AUTOSAR XML (schema 3.1.2)
package /Components/SWC_CoTq
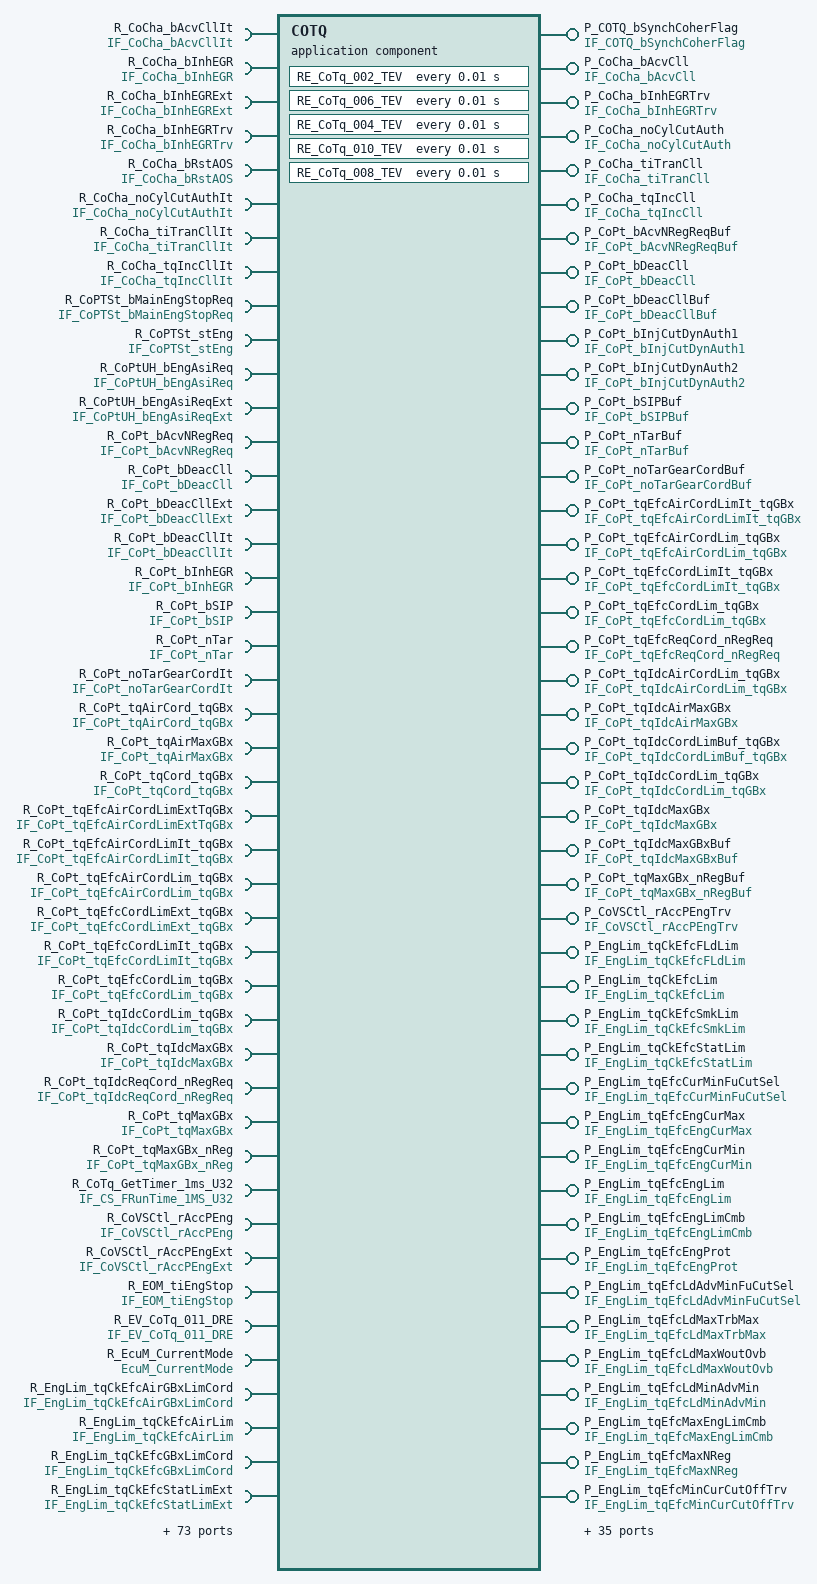
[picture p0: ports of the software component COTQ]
  application software component type COTQ  # CoTq
    79 x provide port:
      P_COTQ_bSynchCoherFlag: unqueued-sender-com-spec{data-element=COTQ_bSynchCoherFlag, can-invalidate=false, init-value=ConstantValue}, provided-interface=IF_COTQ_bSynchCoherFlag  # Requirement: 01552_10_02369-CoTq.I999(0)
      P_CoCha_bAcvCll: unqueued-sender-com-spec{data-element=CoCha_bAcvCll, can-invalidate=false, init-value=ConstantValue1}, provided-interface=IF_CoCha_bAcvCll  # Requirement: 01552_10_02369-CoTq.I010(0)
      P_CoCha_bInhEGRTrv: unqueued-sender-com-spec{data-element=CoCha_bInhEGRTrv, can-invalidate=false, init-value=ConstantValue3}, provided-interface=IF_CoCha_bInhEGRTrv  # Requirement: 01552_10_02369-CoTq.I011(0)
      P_CoCha_noCylCutAuth: unqueued-sender-com-spec{data-element=CoCha_noCylCutAuth, can-invalidate=false, init-value=ConstantValue5}, provided-interface=IF_CoCha_noCylCutAuth  # Requirement: 01552_10_02369-CoTq.I012(0)
      P_CoCha_tiTranCll: unqueued-sender-com-spec{data-element=CoCha_tiTranCll, can-invalidate=false, init-value=ConstantValue7}, provided-interface=IF_CoCha_tiTranCll  # Requirement: 01552_10_02369-CoTq.I013(0)
      P_CoCha_tqIncCll: unqueued-sender-com-spec{data-element=CoCha_tqIncCll, can-invalidate=false, init-value=ConstantValue9}, provided-interface=IF_CoCha_tqIncCll  # Requirement: 01552_10_02369-CoTq.I014(0)
      P_CoPt_bAcvNRegReqBuf: unqueued-sender-com-spec{data-element=CoPt_bAcvNRegReqBuf, can-invalidate=false, init-value=ConstantValue11}, provided-interface=IF_CoPt_bAcvNRegReqBuf  # Requirement: 01552_10_02369-CoTq.I179(0)
      P_CoPt_bDeacCll: unqueued-sender-com-spec{data-element=CoPt_bDeacCll, can-invalidate=false, init-value=ConstantValue13}, provided-interface=IF_CoPt_bDeacCll  # Requirement: 01552_10_02369-CoTq.I015(0)
      P_CoPt_bDeacCllBuf: unqueued-sender-com-spec{data-element=CoPt_bDeacCllBuf, can-invalidate=false, init-value=ConstantValue15}, provided-interface=IF_CoPt_bDeacCllBuf  # Requirement: 01552_10_02369-CoTq.I180(0)
      P_CoPt_bInjCutDynAuth1: unqueued-sender-com-spec{data-element=CoPt_bInjCutDynAuth1, can-invalidate=false, init-value=ConstantValue17}, provided-interface=IF_CoPt_bInjCutDynAuth1  # Requirement: 01552_10_02369-CoTq.I181(0)
      P_CoPt_bInjCutDynAuth2: unqueued-sender-com-spec{data-element=CoPt_bInjCutDynAuth2, can-invalidate=false, init-value=ConstantValue19}, provided-interface=IF_CoPt_bInjCutDynAuth2  # Requirement: 01552_10_02369-CoTq.I182(0)
      P_CoPt_bSIPBuf: unqueued-sender-com-spec{data-element=CoPt_bSIPBuf, can-invalidate=false, init-value=ConstantValue21}, provided-interface=IF_CoPt_bSIPBuf  # Requirement: 01552_10_02369-CoTq.I183(0)
      P_CoPt_nTarBuf: unqueued-sender-com-spec{data-element=CoPt_nTarBuf, can-invalidate=false, init-value=ConstantValue23}, provided-interface=IF_CoPt_nTarBuf  # Requirement: 01552_10_02369-CoTq.I185(0)
      P_CoPt_noTarGearCordBuf: unqueued-sender-com-spec{data-element=CoPt_noTarGearCordBuf, can-invalidate=false, init-value=ConstantValue25}, provided-interface=IF_CoPt_noTarGearCordBuf  # Requirement: 01552_10_02369-CoTq.I184(0)
      P_CoPt_tqEfcAirCordLimIt_tqGBx: unqueued-sender-com-spec{data-element=CoPt_tqEfcAirCordLimIt_tqGBx, can-invalidate=false, init-value=ConstantValue27}, provided-interface=IF_CoPt_tqEfcAirCordLimIt_tqGBx  # Requirement: 01552_10_02369-CoTq.I001(0)
      P_CoPt_tqEfcAirCordLim_tqGBx: unqueued-sender-com-spec{data-element=CoPt_tqEfcAirCordLim_tqGBx, can-invalidate=false, init-value=ConstantValue29}, provided-interface=IF_CoPt_tqEfcAirCordLim_tqGBx  # Requirement: 01552_10_02369-CoTq.I016(0)
      P_CoPt_tqEfcCordLimIt_tqGBx: unqueued-sender-com-spec{data-element=CoPt_tqEfcCordLimIt_tqGBx, can-invalidate=false, init-value=ConstantValue31}, provided-interface=IF_CoPt_tqEfcCordLimIt_tqGBx  # Requirement: 01552_10_02369-CoTq.I002(0)
      P_CoPt_tqEfcCordLim_tqGBx: unqueued-sender-com-spec{data-element=CoPt_tqEfcCordLim_tqGBx, can-invalidate=false, init-value=ConstantValue33}, provided-interface=IF_CoPt_tqEfcCordLim_tqGBx  # Requirement: 01552_10_02369-CoTq.I017(0)
      P_CoPt_tqEfcReqCord_nRegReq: unqueued-sender-com-spec{data-element=CoPt_tqEfcReqCord_nRegReq, can-invalidate=false, init-value=ConstantValue35}, provided-interface=IF_CoPt_tqEfcReqCord_nRegReq  # Requirement: 01552_10_02369-CoTq.I105(0)
      P_CoPt_tqIdcAirCordLim_tqGBx: unqueued-sender-com-spec{data-element=CoPt_tqIdcAirCordLim_tqGBx, can-invalidate=false, init-value=ConstantValue37}, provided-interface=IF_CoPt_tqIdcAirCordLim_tqGBx  # Requirement: 01552_10_02369-CoTq.I084(0)
      P_CoPt_tqIdcAirMaxGBx: unqueued-sender-com-spec{data-element=CoPt_tqIdcAirMaxGBx, can-invalidate=false, init-value=ConstantValue39}, provided-interface=IF_CoPt_tqIdcAirMaxGBx  # Requirement: 01552_10_02369-CoTq.I085(0)
      P_CoPt_tqIdcCordLimBuf_tqGBx: unqueued-sender-com-spec{data-element=CoPt_tqIdcCordLimBuf_tqGBx, can-invalidate=false, init-value=ConstantValue41}, provided-interface=IF_CoPt_tqIdcCordLimBuf_tqGBx  # Requirement: 01552_10_02369-CoTq.I186(0)
      P_CoPt_tqIdcCordLim_tqGBx: unqueued-sender-com-spec{data-element=CoPt_tqIdcCordLim_tqGBx, can-invalidate=false, init-value=ConstantValue43}, provided-interface=IF_CoPt_tqIdcCordLim_tqGBx  # Requirement: 01552_10_02369-CoTq.I086(0)
      P_CoPt_tqIdcMaxGBx: unqueued-sender-com-spec{data-element=CoPt_tqIdcMaxGBx, can-invalidate=false, init-value=ConstantValue45}, provided-interface=IF_CoPt_tqIdcMaxGBx  # Requirement: 01552_10_02369-CoTq.I087(0)
      P_CoPt_tqIdcMaxGBxBuf: unqueued-sender-com-spec{data-element=CoPt_tqIdcMaxGBxBuf, can-invalidate=false, init-value=ConstantValue47}, provided-interface=IF_CoPt_tqIdcMaxGBxBuf  # Requirement: 01552_10_02369-CoTq.I187(0)
      P_CoPt_tqMaxGBx_nRegBuf: unqueued-sender-com-spec{data-element=CoPt_tqMaxGBx_nRegBuf, can-invalidate=false, init-value=ConstantValue49}, provided-interface=IF_CoPt_tqMaxGBx_nRegBuf  # Requirement: 01552_10_02369-CoTq.I188(0)
      P_CoVSCtl_rAccPEngTrv: unqueued-sender-com-spec{data-element=CoVSCtl_rAccPEngTrv, can-invalidate=false, init-value=ConstantValue51}, provided-interface=IF_CoVSCtl_rAccPEngTrv  # Requirement: 01552_10_02369-CoTq.I018(0)
      P_EngLim_tqCkEfcFLdLim: unqueued-sender-com-spec{data-element=EngLim_tqCkEfcFLdLim, can-invalidate=false, init-value=ConstantValue53}, provided-interface=IF_EngLim_tqCkEfcFLdLim  # Requirement: 01552_10_02369-CoTq.I118(0)
      P_EngLim_tqCkEfcLim: unqueued-sender-com-spec{data-element=EngLim_tqCkEfcLim, can-invalidate=false, init-value=ConstantValue55}, provided-interface=IF_EngLim_tqCkEfcLim  # Requirement: 01552_10_02369-CoTq.I119(0)
      P_EngLim_tqCkEfcSmkLim: unqueued-sender-com-spec{data-element=EngLim_tqCkEfcSmkLim, can-invalidate=false, init-value=ConstantValue57}, provided-interface=IF_EngLim_tqCkEfcSmkLim  # Requirement: 01552_10_02369-CoTq.I120(0)
      P_EngLim_tqCkEfcStatLim: unqueued-sender-com-spec{data-element=EngLim_tqCkEfcStatLim, can-invalidate=false, init-value=ConstantValue59}, provided-interface=IF_EngLim_tqCkEfcStatLim  # Requirement: 01552_10_02369-CoTq.I019(0)
      P_EngLim_tqEfcCurMinFuCutSel: unqueued-sender-com-spec{data-element=EngLim_tqEfcCurMinFuCutSel, can-invalidate=false, init-value=ConstantValue61}, provided-interface=IF_EngLim_tqEfcCurMinFuCutSel  # Requirement: 01552_10_02369-CoTq.I106(0)
      P_EngLim_tqEfcEngCurMax: unqueued-sender-com-spec{data-element=EngLim_tqEfcEngCurMax, can-invalidate=false, init-value=ConstantValue63}, provided-interface=IF_EngLim_tqEfcEngCurMax  # Requirement: 01552_10_02369-CoTq.I121(0)
      P_EngLim_tqEfcEngCurMin: unqueued-sender-com-spec{data-element=EngLim_tqEfcEngCurMin, can-invalidate=false, init-value=ConstantValue65}, provided-interface=IF_EngLim_tqEfcEngCurMin  # Requirement: 01552_10_02369-CoTq.I107(0)
      P_EngLim_tqEfcEngLim: unqueued-sender-com-spec{data-element=EngLim_tqEfcEngLim, can-invalidate=false, init-value=ConstantValue67}, provided-interface=IF_EngLim_tqEfcEngLim  # Requirement: 01552_10_02369-CoTq.I108(0)
      P_EngLim_tqEfcEngLimCmb: unqueued-sender-com-spec{data-element=EngLim_tqEfcEngLimCmb, can-invalidate=false, init-value=ConstantValue69}, provided-interface=IF_EngLim_tqEfcEngLimCmb  # Requirement: 01552_10_02369-CoTq.I109(0)
      P_EngLim_tqEfcEngProt: unqueued-sender-com-spec{data-element=EngLim_tqEfcEngProt, can-invalidate=false, init-value=ConstantValue71}, provided-interface=IF_EngLim_tqEfcEngProt  # Requirement: 01552_10_02369-CoTq.I122(0)
      P_EngLim_tqEfcLdAdvMinFuCutSel: unqueued-sender-com-spec{data-element=EngLim_tqEfcLdAdvMinFuCutSel, can-invalidate=false, init-value=ConstantValue73}, provided-interface=IF_EngLim_tqEfcLdAdvMinFuCutSel  # Requirement: 01552_10_02369-CoTq.I110(0)
      P_EngLim_tqEfcLdMaxTrbMax: unqueued-sender-com-spec{data-element=EngLim_tqEfcLdMaxTrbMax, can-invalidate=false, init-value=ConstantValue75}, provided-interface=IF_EngLim_tqEfcLdMaxTrbMax  # Requirement: 01552_10_02369-CoTq.I123(0)
      P_EngLim_tqEfcLdMaxWoutOvb: unqueued-sender-com-spec{data-element=EngLim_tqEfcLdMaxWoutOvb, can-invalidate=false, init-value=ConstantValue77}, provided-interface=IF_EngLim_tqEfcLdMaxWoutOvb  # Requirement: 01552_10_02369-CoTq.I111(0)
      P_EngLim_tqEfcLdMinAdvMin: unqueued-sender-com-spec{data-element=EngLim_tqEfcLdMinAdvMin, can-invalidate=false, init-value=ConstantValue79}, provided-interface=IF_EngLim_tqEfcLdMinAdvMin  # Requirement: 01552_10_02369-CoTq.I112(0)
      P_EngLim_tqEfcMaxEngLimCmb: unqueued-sender-com-spec{data-element=EngLim_tqEfcMaxEngLimCmb, can-invalidate=false, init-value=ConstantValue81}, provided-interface=IF_EngLim_tqEfcMaxEngLimCmb  # Requirement: 01552_10_02369-CoTq.I113(0)
      P_EngLim_tqEfcMaxNReg: unqueued-sender-com-spec{data-element=EngLim_tqEfcMaxNReg, can-invalidate=false, init-value=ConstantValue83}, provided-interface=IF_EngLim_tqEfcMaxNReg  # Requirement: 01552_10_02369-CoTq.I124(0)
      P_EngLim_tqEfcMinCurCutOffTrv: unqueued-sender-com-spec{data-element=EngLim_tqEfcMinCurCutOffTrv, can-invalidate=false, init-value=ConstantValue85}, provided-interface=IF_EngLim_tqEfcMinCurCutOffTrv  # Requirement: 01552_10_02369-CoTq.I125(0)
      P_EngLim_tqEfcMinCurTrv: unqueued-sender-com-spec{data-element=EngLim_tqEfcMinCurTrv, can-invalidate=false, init-value=ConstantValue87}, provided-interface=IF_EngLim_tqEfcMinCurTrv  # Requirement: 01552_10_02369-CoTq.I126(0)
      P_EngLim_tqEfcMinEngLimCmb: unqueued-sender-com-spec{data-element=EngLim_tqEfcMinEngLimCmb, can-invalidate=false, init-value=ConstantValue89}, provided-interface=IF_EngLim_tqEfcMinEngLimCmb  # Requirement: 01552_10_02369-CoTq.I114(0)
      P_EngLim_tqEfcPresUsThrMax: unqueued-sender-com-spec{data-element=EngLim_tqEfcPresUsThrMax, can-invalidate=false, init-value=ConstantValue91}, provided-interface=IF_EngLim_tqEfcPresUsThrMax  # Requirement: 01552_10_02369-CoTq.I127(0)
      P_EngLim_tqEfcRed: unqueued-sender-com-spec{data-element=EngLim_tqEfcRed, can-invalidate=false, init-value=ConstantValue93}, provided-interface=IF_EngLim_tqEfcRed  # Requirement: 01552_10_02369-CoTq.I128(0)
      P_EngLim_tqEfcSfty: unqueued-sender-com-spec{data-element=EngLim_tqEfcSfty, can-invalidate=false, init-value=ConstantValue95}, provided-interface=IF_EngLim_tqEfcSfty  # Requirement: 01552_10_02369-CoTq.I129(0)
      P_EngLim_tqEfcSyst: unqueued-sender-com-spec{data-element=EngLim_tqEfcSyst, can-invalidate=false, init-value=ConstantValue97}, provided-interface=IF_EngLim_tqEfcSyst  # Requirement: 01552_10_02369-CoTq.I130(0)
      P_ThMgt_tqEfcLimAntiBoilProt: unqueued-sender-com-spec{data-element=ThMgt_tqEfcLimAntiBoilProt, can-invalidate=false, init-value=ConstantValue99}, provided-interface=IF_ThMgt_tqEfcLimAntiBoilProt  # Requirement: 01552_10_02369-CoTq.I131(0)
      P_TqDem_facGainFilTrv_nCk: unqueued-sender-com-spec{data-element=TqDem_facGainFilTrv_nCk, can-invalidate=false, init-value=ConstantValue101}, provided-interface=IF_TqDem_facGainFilTrv_nCk  # Requirement: 01552_10_02369-CoTq.I020(0)
      P_TqDem_tqCkEfcTrv: unqueued-sender-com-spec{data-element=TqDem_tqCkEfcTrv, can-invalidate=false, init-value=ConstantValue103}, provided-interface=IF_TqDem_tqCkEfcTrv  # Requirement: 01552_10_02369-CoTq.I009(0)
      P_TqLimEM_tqIdcLimEM: unqueued-sender-com-spec{data-element=TqLimEM_tqIdcLimEM, can-invalidate=false, init-value=ConstantValue105}, provided-interface=IF_TqLimEM_tqIdcLimEM  # Requirement: 01552_10_02369-CoTq.I088(0)
      P_TqLimEM_tqLimEMTrv: unqueued-sender-com-spec{data-element=TqLimEM_tqLimEMTrv, can-invalidate=false, init-value=ConstantValue107}, provided-interface=IF_TqLimEM_tqLimEMTrv  # Requirement: 01552_10_02369-CoTq.I021(0)
      P_TqSys_bAcceClrCrossAOS: unqueued-sender-com-spec{data-element=TqSys_bAcceClrCrossAOS, can-invalidate=false, init-value=ConstantValue109}, provided-interface=IF_TqSys_bAcceClrCrossAOS  # Requirement: 01552_10_02369-CoTq.I022(0)
      P_TqSys_bAcceDetAOS: unqueued-sender-com-spec{data-element=TqSys_bAcceDetAOS, can-invalidate=false, init-value=ConstantValue111}, provided-interface=IF_TqSys_bAcceDetAOS  # Requirement: 01552_10_02369-CoTq.I023(0)
      P_TqSys_bAcvCll: unqueued-sender-com-spec{data-element=TqSys_bAcvCll, can-invalidate=false, init-value=ConstantValue113}, provided-interface=IF_TqSys_bAcvCll  # Requirement: 01552_10_02369-CoTq.I024(0)
      P_TqSys_bDeceAcv: unqueued-sender-com-spec{data-element=TqSys_bDeceAcv, can-invalidate=false, init-value=ConstantValue115}, provided-interface=IF_TqSys_bDeceAcv  # Requirement: 01552_10_02369-CoTq.I025(0)
      P_TqSys_bDeceDetAOS: unqueued-sender-com-spec{data-element=TqSys_bDeceDetAOS, can-invalidate=false, init-value=ConstantValue117}, provided-interface=IF_TqSys_bDeceDetAOS  # Requirement: 01552_10_02369-CoTq.I026(0)
      P_TqSys_bEngAsiReqTrv: unqueued-sender-com-spec{data-element=TqSys_bEngAsiReqTrv, can-invalidate=false, init-value=ConstantValue119}, provided-interface=IF_TqSys_bEngAsiReqTrv  # Requirement: 01552_10_02369-CoTq.I027(0)
      P_TqSys_bInhEGR: unqueued-sender-com-spec{data-element=TqSys_bInhEGR, can-invalidate=false, init-value=ConstantValue121}, provided-interface=IF_TqSys_bInhEGR  # Requirement: 01552_10_02369-CoTq.I089(0)
      P_TqSys_bRstAOS: unqueued-sender-com-spec{data-element=TqSys_bRstAOS, can-invalidate=false, init-value=ConstantValue123}, provided-interface=IF_TqSys_bRstAOS  # Requirement: 01552_10_02369-CoTq.I090(0)
      P_TqSys_noCylCutAuth: unqueued-sender-com-spec{data-element=TqSys_noCylCutAuth, can-invalidate=false, init-value=ConstantValue125}, provided-interface=IF_TqSys_noCylCutAuth  # Requirement: 01552_10_02369-CoTq.I028(0)
      P_TqSys_rLdEngRef: unqueued-sender-com-spec{data-element=TqSys_rLdEngRef, can-invalidate=false, init-value=ConstantValue127}, provided-interface=IF_TqSys_rLdEngRef  # Requirement: 01552_10_02369-CoTq.I115(0)
      P_TqSys_stDrivFilPha: unqueued-sender-com-spec{data-element=TqSys_stDrivFilPha, can-invalidate=false, init-value=ConstantValue129}, provided-interface=IF_TqSys_stDrivFilPha  # Requirement: 01552_10_02369-CoTq.I029(0)
      P_TqSys_tiTranCll: unqueued-sender-com-spec{data-element=TqSys_tiTranCll, can-invalidate=false, init-value=ConstantValue131}, provided-interface=IF_TqSys_tiTranCll  # Requirement: 01552_10_02369-CoTq.I030(0)
      P_TqSys_tqCkDeceIni: unqueued-sender-com-spec{data-element=TqSys_tqCkDeceIni, can-invalidate=false, init-value=ConstantValue133}, provided-interface=IF_TqSys_tqCkDeceIni  # Requirement: 01552_10_02369-CoTq.I031(0)
      P_TqSys_tqCkEfcFilTrv: unqueued-sender-com-spec{data-element=TqSys_tqCkEfcFilTrv, can-invalidate=false, init-value=ConstantValue135}, provided-interface=IF_TqSys_tqCkEfcFilTrv  # Requirement: 01552_10_02369-CoTq.I032(0)
      P_TqSys_tqCkEfcMinFeas: unqueued-sender-com-spec{data-element=TqSys_tqCkEfcMinFeas, can-invalidate=false, init-value=ConstantValue137}, provided-interface=IF_TqSys_tqCkEfcMinFeas  # Requirement: 01552_10_02369-CoTq.I132(0)
      P_TqSys_tqCkEfcReq: unqueued-sender-com-spec{data-element=TqSys_tqCkEfcReq, can-invalidate=false, init-value=ConstantValue139}, provided-interface=IF_TqSys_tqCkEfcReq  # Requirement: 01552_10_02369-CoTq.I133(0)
      P_TqSys_tqCkEngReal: unqueued-sender-com-spec{data-element=TqSys_tqCkEngReal, can-invalidate=false, init-value=ConstantValue141}, provided-interface=IF_TqSys_tqCkEngReal  # Requirement: 01552_10_02369-CoTq.I134(0)
      P_TqSys_tqCkEngRealEM: unqueued-sender-com-spec{data-element=TqSys_tqCkEngRealEM, can-invalidate=false, init-value=ConstantValue143}, provided-interface=IF_TqSys_tqCkEngRealEM  # Requirement: 01552_10_02369-CoTq.I116(0)
      P_TqSys_tqEfcAirIdl: unqueued-sender-com-spec{data-element=TqSys_tqEfcAirIdl, can-invalidate=false, init-value=ConstantValue145}, provided-interface=IF_TqSys_tqEfcAirIdl  # Requirement: 01552_10_02369-CoTq.I135(0)
      P_TqSys_tqEfcEngWoutAOS: unqueued-sender-com-spec{data-element=TqSys_tqEfcEngWoutAOS, can-invalidate=false, init-value=ConstantValue147}, provided-interface=IF_TqSys_tqEfcEngWoutAOS  # Requirement: 01552_10_02369-CoTq.I117(0)
      P_TqSys_tqEfcIdl: unqueued-sender-com-spec{data-element=TqSys_tqEfcIdl, can-invalidate=false, init-value=ConstantValue149}, provided-interface=IF_TqSys_tqEfcIdl  # Requirement: 01552_10_02369-CoTq.I136(0)
      P_TqSys_tqIdcAirLim: unqueued-sender-com-spec{data-element=TqSys_tqIdcAirLim, can-invalidate=false, init-value=ConstantValue151}, provided-interface=IF_TqSys_tqIdcAirLim  # Requirement: 01552_10_02369-CoTq.I091(0)
      P_TqSys_tqIncCll: unqueued-sender-com-spec{data-element=TqSys_tqIncCll, can-invalidate=false, init-value=ConstantValue153}, provided-interface=IF_TqSys_tqIncCll  # Requirement: 01552_10_02369-CoTq.I033(0)
      P_TqSys_tqThdPha3: unqueued-sender-com-spec{data-element=TqSys_tqThdPha3, can-invalidate=false, init-value=ConstantValue155}, provided-interface=IF_TqSys_tqThdPha3  # Requirement: 01552_10_02369-CoTq.I034(0)
    117 x require port:
      R_CoCha_bAcvCllIt: unqueued-receiver-com-spec{data-element=CoCha_bAcvCllIt, init-value=ConstantValue157, resync-time=0}, required-interface=IF_CoCha_bAcvCllIt  # Requirement: 01552_10_02369-CoTq.I035(0)
      R_CoCha_bInhEGR: unqueued-receiver-com-spec{data-element=CoCha_bInhEGR, init-value=ConstantValue159, resync-time=0}, required-interface=IF_CoCha_bInhEGR  # Requirement: 01552_10_02369-CoTq.I036(0)
      R_CoCha_bInhEGRExt: unqueued-receiver-com-spec{data-element=CoCha_bInhEGRExt, init-value=ConstantValue161, resync-time=0}, required-interface=IF_CoCha_bInhEGRExt  # Requirement: 01552_10_02369-CoTq.I037(0)
      R_CoCha_bInhEGRTrv: unqueued-receiver-com-spec{data-element=CoCha_bInhEGRTrv, init-value=ConstantValue163, resync-time=0}, required-interface=IF_CoCha_bInhEGRTrv  # Requirement: 01552_10_02369-CoTq.I092(0)
      R_CoCha_bRstAOS: unqueued-receiver-com-spec{data-element=CoCha_bRstAOS, init-value=ConstantValue165, resync-time=0}, required-interface=IF_CoCha_bRstAOS  # Requirement: 01552_10_02369-CoTq.I093(0)
      R_CoCha_noCylCutAuthIt: unqueued-receiver-com-spec{data-element=CoCha_noCylCutAuthIt, init-value=ConstantValue167, resync-time=0}, required-interface=IF_CoCha_noCylCutAuthIt  # Requirement: 01552_10_02369-CoTq.I038(0)
      R_CoCha_tiTranCllIt: unqueued-receiver-com-spec{data-element=CoCha_tiTranCllIt, init-value=ConstantValue169, resync-time=0}, required-interface=IF_CoCha_tiTranCllIt  # Requirement: 01552_10_02369-CoTq.I039(0)
      R_CoCha_tqIncCllIt: unqueued-receiver-com-spec{data-element=CoCha_tqIncCllIt, init-value=ConstantValue171, resync-time=0}, required-interface=IF_CoCha_tqIncCllIt  # Requirement: 01552_10_02369-CoTq.I040(0)
      R_CoPTSt_bMainEngStopReq: unqueued-receiver-com-spec{data-element=CoPTSt_bMainEngStopReq, init-value=ConstantValue173, resync-time=0}, required-interface=IF_CoPTSt_bMainEngStopReq  # Requirement: 01552_10_02369-CoTq.I138(0)
      R_CoPTSt_stEng: unqueued-receiver-com-spec{data-element=CoPTSt_stEng, init-value=ConstantValue175, resync-time=0}, required-interface=IF_CoPTSt_stEng  # Requirement: 01552_10_02369-CoTq.I139(0)
      R_CoPtUH_bEngAsiReq: unqueued-receiver-com-spec{data-element=CoPtUH_bEngAsiReq, init-value=ConstantValue177, resync-time=0}, required-interface=IF_CoPtUH_bEngAsiReq  # Requirement: 01552_10_02369-CoTq.I047(0)
      R_CoPtUH_bEngAsiReqExt: unqueued-receiver-com-spec{data-element=CoPtUH_bEngAsiReqExt, init-value=ConstantValue179, resync-time=0}, required-interface=IF_CoPtUH_bEngAsiReqExt  # Requirement: 01552_10_02369-CoTq.I048(0)
      R_CoPt_bAcvNRegReq: unqueued-receiver-com-spec{data-element=CoPt_bAcvNRegReq, init-value=ConstantValue181, resync-time=0}, required-interface=IF_CoPt_bAcvNRegReq  # Requirement: 01552_10_02369-CoTq.I189(0)
      R_CoPt_bDeacCll: unqueued-receiver-com-spec{data-element=CoPt_bDeacCll, init-value=ConstantValue183, resync-time=0}, required-interface=IF_CoPt_bDeacCll  # Requirement: 01552_10_02369-CoTq.I015(0)
      R_CoPt_bDeacCllExt: unqueued-receiver-com-spec{data-element=CoPt_bDeacCllExt, init-value=ConstantValue185, resync-time=0}, required-interface=IF_CoPt_bDeacCllExt  # Requirement: 01552_10_02369-CoTq.I041(0)
      R_CoPt_bDeacCllIt: unqueued-receiver-com-spec{data-element=CoPt_bDeacCllIt, init-value=ConstantValue187, resync-time=0}, required-interface=IF_CoPt_bDeacCllIt  # Requirement: 01552_10_02369-CoTq.I042(0)
      R_CoPt_bInhEGR: unqueued-receiver-com-spec{data-element=CoPt_bInhEGR, init-value=ConstantValue189, resync-time=0}, required-interface=IF_CoPt_bInhEGR  # Requirement: 01552_10_02369-CoTq.I094(0)
      R_CoPt_bSIP: unqueued-receiver-com-spec{data-element=CoPt_bSIP, init-value=ConstantValue191, resync-time=0}, required-interface=IF_CoPt_bSIP  # Requirement: 01552_10_02369-CoTq.I191(0)
      R_CoPt_nTar: unqueued-receiver-com-spec{data-element=CoPt_nTar, init-value=ConstantValue193, resync-time=0}, required-interface=IF_CoPt_nTar  # Requirement: 01552_10_02369-CoTq.I193(0)
      R_CoPt_noTarGearCordIt: unqueued-receiver-com-spec{data-element=CoPt_noTarGearCordIt, init-value=ConstantValue195, resync-time=0}, required-interface=IF_CoPt_noTarGearCordIt  # Requirement: 01552_10_02369-CoTq.I192(0)
      R_CoPt_tqAirCord_tqGBx: unqueued-receiver-com-spec{data-element=CoPt_tqAirCord_tqGBx, init-value=ConstantValue197, resync-time=0}, required-interface=IF_CoPt_tqAirCord_tqGBx  # Requirement: 01552_10_02369-CoTq.I003(0)
      R_CoPt_tqAirMaxGBx: unqueued-receiver-com-spec{data-element=CoPt_tqAirMaxGBx, init-value=ConstantValue199, resync-time=0}, required-interface=IF_CoPt_tqAirMaxGBx  # Requirement: 01552_10_02369-CoTq.I095(0)
      R_CoPt_tqCord_tqGBx: unqueued-receiver-com-spec{data-element=CoPt_tqCord_tqGBx, init-value=ConstantValue201, resync-time=0}, required-interface=IF_CoPt_tqCord_tqGBx  # Requirement: 01552_10_02369-CoTq.I004(0)
      R_CoPt_tqEfcAirCordLimExtTqGBx: unqueued-receiver-com-spec{data-element=CoPt_tqEfcAirCordLimExtTqGBx, init-value=ConstantValue203, resync-time=0}, required-interface=IF_CoPt_tqEfcAirCordLimExtTqGBx  # Requirement: 01552_10_02369-CoTq.I043(0)
      R_CoPt_tqEfcAirCordLimIt_tqGBx: unqueued-receiver-com-spec{data-element=CoPt_tqEfcAirCordLimIt_tqGBx, init-value=ConstantValue205, resync-time=0}, required-interface=IF_CoPt_tqEfcAirCordLimIt_tqGBx  # Requirement: 01552_10_02369-CoTq.I001(0)
      R_CoPt_tqEfcAirCordLim_tqGBx: unqueued-receiver-com-spec{data-element=CoPt_tqEfcAirCordLim_tqGBx, init-value=ConstantValue207, resync-time=0}, required-interface=IF_CoPt_tqEfcAirCordLim_tqGBx  # Requirement: 01552_10_02369-CoTq.I096(0)
      R_CoPt_tqEfcCordLimExt_tqGBx: unqueued-receiver-com-spec{data-element=CoPt_tqEfcCordLimExt_tqGBx, init-value=ConstantValue209, resync-time=0}, required-interface=IF_CoPt_tqEfcCordLimExt_tqGBx  # Requirement: 01552_10_02369-CoTq.I045(0)
      R_CoPt_tqEfcCordLimIt_tqGBx: unqueued-receiver-com-spec{data-element=CoPt_tqEfcCordLimIt_tqGBx, init-value=ConstantValue211, resync-time=0}, required-interface=IF_CoPt_tqEfcCordLimIt_tqGBx  # Requirement: 01552_10_02369-CoTq.I002(0)
      R_CoPt_tqEfcCordLim_tqGBx: unqueued-receiver-com-spec{data-element=CoPt_tqEfcCordLim_tqGBx, init-value=ConstantValue213, resync-time=0}, required-interface=IF_CoPt_tqEfcCordLim_tqGBx  # Requirement: 01552_10_02369-CoTq.I097(0)
      R_CoPt_tqIdcCordLim_tqGBx: unqueued-receiver-com-spec{data-element=CoPt_tqIdcCordLim_tqGBx, init-value=ConstantValue215, resync-time=0}, required-interface=IF_CoPt_tqIdcCordLim_tqGBx  # Requirement: 01552_10_02369-CoTq.I086(0)
      R_CoPt_tqIdcMaxGBx: unqueued-receiver-com-spec{data-element=CoPt_tqIdcMaxGBx, init-value=ConstantValue217, resync-time=0}, required-interface=IF_CoPt_tqIdcMaxGBx  # Requirement: 01552_10_02369-CoTq.I087(0)
      R_CoPt_tqIdcReqCord_nRegReq: unqueued-receiver-com-spec{data-element=CoPt_tqIdcReqCord_nRegReq, init-value=ConstantValue219, resync-time=0}, required-interface=IF_CoPt_tqIdcReqCord_nRegReq  # Requirement: 01552_10_02369-CoTq.I137(0)
      R_CoPt_tqMaxGBx: unqueued-receiver-com-spec{data-element=CoPt_tqMaxGBx, init-value=ConstantValue221, resync-time=0}, required-interface=IF_CoPt_tqMaxGBx  # Requirement: 01552_10_02369-CoTq.I098(0)
      R_CoPt_tqMaxGBx_nReg: unqueued-receiver-com-spec{data-element=CoPt_tqMaxGBx_nReg, init-value=ConstantValue223, resync-time=0}, required-interface=IF_CoPt_tqMaxGBx_nReg  # Requirement: 01552_10_02369-CoTq.I196(0)
      R_CoTq_GetTimer_1ms_U32: required-interface=IF_CS_FRunTime_1MS_U32
      R_CoVSCtl_rAccPEng: unqueued-receiver-com-spec{data-element=CoVSCtl_rAccPEng, init-value=ConstantValue225, resync-time=0}, required-interface=IF_CoVSCtl_rAccPEng  # Requirement: 01552_10_02369-CoTq.I049(0)
      R_CoVSCtl_rAccPEngExt: unqueued-receiver-com-spec{data-element=CoVSCtl_rAccPEngExt, init-value=ConstantValue227, resync-time=0}, required-interface=IF_CoVSCtl_rAccPEngExt  # Requirement: 01552_10_02369-CoTq.I050(0)
      R_EOM_tiEngStop: unqueued-receiver-com-spec{data-element=EOM_tiEngStop, init-value=ConstantValue229, resync-time=0}, required-interface=IF_EOM_tiEngStop  # Requirement: 01552_10_02369-CoTq.I159(0)
      R_EV_CoTq_011_DRE: unqueued-receiver-com-spec{data-element=EV_CoTq_011_DRE, init-value=ConstantValue231, resync-time=0}, required-interface=IF_EV_CoTq_011_DRE
      R_EcuM_CurrentMode: required-interface=EcuM_CurrentMode  # Requirement: 01552_09_00532-SSTG-C007(0)
      R_EngLim_tqCkEfcAirGBxLimCord: unqueued-receiver-com-spec{data-element=EngLim_tqCkEfcAirGBxLimCord, init-value=ConstantValue233, resync-time=0}, required-interface=IF_EngLim_tqCkEfcAirGBxLimCord  # Requirement: 01552_10_02369-CoTq.I005(0)
      R_EngLim_tqCkEfcAirLim: unqueued-receiver-com-spec{data-element=EngLim_tqCkEfcAirLim, init-value=ConstantValue235, resync-time=0}, required-interface=IF_EngLim_tqCkEfcAirLim  # Requirement: 01552_10_02369-CoTq.I099(0)
      R_EngLim_tqCkEfcGBxLimCord: unqueued-receiver-com-spec{data-element=EngLim_tqCkEfcGBxLimCord, init-value=ConstantValue237, resync-time=0}, required-interface=IF_EngLim_tqCkEfcGBxLimCord  # Requirement: 01552_10_02369-CoTq.I006(0)
      R_EngLim_tqCkEfcStatLimExt: unqueued-receiver-com-spec{data-element=EngLim_tqCkEfcStatLimExt, init-value=ConstantValue239, resync-time=0}, required-interface=IF_EngLim_tqCkEfcStatLimExt  # Requirement: 01552_10_02369-CoTq.I051(0)
      R_EngLim_tqCkEfcStatLimIt: unqueued-receiver-com-spec{data-element=EngLim_tqCkEfcStatLimIt, init-value=ConstantValue241, resync-time=0}, required-interface=IF_EngLim_tqCkEfcStatLimIt  # Requirement: 01552_10_02369-CoTq.I052(0)
      R_EngLim_tqIdcEngCur: unqueued-receiver-com-spec{data-element=EngLim_tqIdcEngCur, init-value=ConstantValue243, resync-time=0}, required-interface=IF_EngLim_tqIdcEngCur  # Requirement: 01552_10_02369-CoTq.I140(0)
      R_EngLim_tqIdcEngCurGBx: unqueued-receiver-com-spec{data-element=EngLim_tqIdcEngCurGBx, init-value=ConstantValue245, resync-time=0}, required-interface=IF_EngLim_tqIdcEngCurGBx  # Requirement: 01552_10_02369-CoTq.I141(0)
      R_EngLim_tqIdcEngCurMax: unqueued-receiver-com-spec{data-element=EngLim_tqIdcEngCurMax, init-value=ConstantValue247, resync-time=0}, required-interface=IF_EngLim_tqIdcEngCurMax  # Requirement: 01552_10_02369-CoTq.I142(0)
      R_EngLim_tqIdcEngCurMin: unqueued-receiver-com-spec{data-element=EngLim_tqIdcEngCurMin, init-value=ConstantValue249, resync-time=0}, required-interface=IF_EngLim_tqIdcEngCurMin  # Requirement: 01552_10_02369-CoTq.I143(0)
      R_EngLim_tqIdcEngCurMinSelc: unqueued-receiver-com-spec{data-element=EngLim_tqIdcEngCurMinSelc, init-value=ConstantValue251, resync-time=0}, required-interface=IF_EngLim_tqIdcEngCurMinSelc  # Requirement: 01552_10_02369-CoTq.I144(0)
      R_EngLim_tqIdcEngLim: unqueued-receiver-com-spec{data-element=EngLim_tqIdcEngLim, init-value=ConstantValue253, resync-time=0}, required-interface=IF_EngLim_tqIdcEngLim  # Requirement: 01552_10_02369-CoTq.I145(0)
      R_EngLim_tqIdcEngLimMax: unqueued-receiver-com-spec{data-element=EngLim_tqIdcEngLimMax, init-value=ConstantValue255, resync-time=0}, required-interface=IF_EngLim_tqIdcEngLimMax  # Requirement: 01552_10_02369-CoTq.I146(0)
      R_EngLim_tqIdcEngProt: unqueued-receiver-com-spec{data-element=EngLim_tqIdcEngProt, init-value=ConstantValue257, resync-time=0}, required-interface=IF_EngLim_tqIdcEngProt  # Requirement: 01552_10_02369-CoTq.I147(0)
      R_EngLim_tqIdcFLdLim: unqueued-receiver-com-spec{data-element=EngLim_tqIdcFLdLim, init-value=ConstantValue259, resync-time=0}, required-interface=IF_EngLim_tqIdcFLdLim  # Requirement: 01552_10_02369-CoTq.I148(0)
      R_EngLim_tqIdcLdMaxTrbMax: unqueued-receiver-com-spec{data-element=EngLim_tqIdcLdMaxTrbMax, init-value=ConstantValue261, resync-time=0}, required-interface=IF_EngLim_tqIdcLdMaxTrbMax  # Requirement: 01552_10_02369-CoTq.I149(0)
      R_EngLim_tqIdcLdMaxTrbMaxNoOvb: unqueued-receiver-com-spec{data-element=EngLim_tqIdcLdMaxTrbMaxNoOvb, init-value=ConstantValue263, resync-time=0}, required-interface=IF_EngLim_tqIdcLdMaxTrbMaxNoOvb  # Requirement: 01552_10_02369-CoTq.I150(0)
      R_EngLim_tqIdcLdMinAdvMin: unqueued-receiver-com-spec{data-element=EngLim_tqIdcLdMinAdvMin, init-value=ConstantValue265, resync-time=0}, required-interface=IF_EngLim_tqIdcLdMinAdvMin  # Requirement: 01552_10_02369-CoTq.I151(0)
      R_EngLim_tqIdcLdMinAdvMinSelc: unqueued-receiver-com-spec{data-element=EngLim_tqIdcLdMinAdvMinSelc, init-value=ConstantValue267, resync-time=0}, required-interface=IF_EngLim_tqIdcLdMinAdvMinSelc  # Requirement: 01552_10_02369-CoTq.I152(0)
      R_EngLim_tqIdcMaxNReg: unqueued-receiver-com-spec{data-element=EngLim_tqIdcMaxNReg, init-value=ConstantValue269, resync-time=0}, required-interface=IF_EngLim_tqIdcMaxNReg  # Requirement: 01552_10_02369-CoTq.I153(0)
      R_EngLim_tqIdcPresUsThrMax: unqueued-receiver-com-spec{data-element=EngLim_tqIdcPresUsThrMax, init-value=ConstantValue271, resync-time=0}, required-interface=IF_EngLim_tqIdcPresUsThrMax  # Requirement: 01552_10_02369-CoTq.I154(0)
      R_EngLim_tqIdcRed: unqueued-receiver-com-spec{data-element=EngLim_tqIdcRed, init-value=ConstantValue273, resync-time=0}, required-interface=IF_EngLim_tqIdcRed  # Requirement: 01552_10_02369-CoTq.I155(0)
      R_EngLim_tqIdcSfty: unqueued-receiver-com-spec{data-element=EngLim_tqIdcSfty, init-value=ConstantValue275, resync-time=0}, required-interface=IF_EngLim_tqIdcSfty  # Requirement: 01552_10_02369-CoTq.I156(0)
      R_EngLim_tqIdcSmkLim: unqueued-receiver-com-spec{data-element=EngLim_tqIdcSmkLim, init-value=ConstantValue277, resync-time=0}, required-interface=IF_EngLim_tqIdcSmkLim  # Requirement: 01552_10_02369-CoTq.I157(0)
      R_EngLim_tqIdcSyst: unqueued-receiver-com-spec{data-element=EngLim_tqIdcSyst, init-value=ConstantValue279, resync-time=0}, required-interface=IF_EngLim_tqIdcSyst  # Requirement: 01552_10_02369-CoTq.I158(0)
      R_Ext_nEng: unqueued-receiver-com-spec{data-element=Ext_nEng, init-value=ConstantValue281, resync-time=0}, required-interface=IF_Ext_nEng  # Requirement: 01552_10_02369-CoTq.I160(0)
      R_Ext_pAirExtMes: unqueued-receiver-com-spec{data-element=Ext_pAirExtMes, init-value=ConstantValue283, resync-time=0}, required-interface=IF_Ext_pAirExtMes  # Requirement: 01552_10_02369-CoTq.I161(0)
      R_Ext_stTraTypCf: unqueued-receiver-com-spec{data-element=Ext_stTraTypCf, init-value=ConstantValue285, resync-time=0}, required-interface=IF_Ext_stTraTypCf  # Requirement: 01552_10_02369-CoTq.I053(0)
      R_Ext_tAir: unqueued-receiver-com-spec{data-element=Ext_tAir, init-value=ConstantValue287, resync-time=0}, required-interface=IF_Ext_tAir  # Requirement: 01552_10_02369-CoTq.I162(0)
      R_Ext_tCoMes: unqueued-receiver-com-spec{data-element=Ext_tCoMes, init-value=ConstantValue289, resync-time=0}, required-interface=IF_Ext_tCoMes  # Requirement: 01552_10_02369-CoTq.I163(0)
      R_Ext_tOilMes: unqueued-receiver-com-spec{data-element=Ext_tOilMes, init-value=ConstantValue291, resync-time=0}, required-interface=IF_Ext_tOilMes  # Requirement: 01552_10_02369-CoTq.I165(0)
      R_Ext_tiTDC: unqueued-receiver-com-spec{data-element=Ext_tiTDC, init-value=ConstantValue293, resync-time=0}, required-interface=IF_Ext_tiTDC  # Requirement: 01552_10_02369-CoTq.I164(0)
      R_IdlSys_tqIdcAirIdl: unqueued-receiver-com-spec{data-element=IdlSys_tqIdcAirIdl, init-value=ConstantValue295, resync-time=0}, required-interface=IF_IdlSys_tqIdcAirIdl  # Requirement: 01552_10_02369-CoTq.I166(0)
      R_InjSys_tqIdcMinFeas: unqueued-receiver-com-spec{data-element=InjSys_tqIdcMinFeas, init-value=ConstantValue297, resync-time=0}, required-interface=IF_InjSys_tqIdcMinFeas  # Requirement: 01552_10_02369-CoTq.I167(0)
      R_ThMgt_tqIdcLimReq: unqueued-receiver-com-spec{data-element=ThMgt_tqIdcLimReq, init-value=ConstantValue299, resync-time=0}, required-interface=IF_ThMgt_tqIdcLimReq  # Requirement: 01552_10_02369-CoTq.I168(0)
      R_TqCmp_tqAltLoss: unqueued-receiver-com-spec{data-element=TqCmp_tqAltLoss, init-value=ConstantValue301, resync-time=0}, required-interface=IF_TqCmp_tqAltLoss  # Requirement: 01552_10_02369-CoTq.I100(0)
      R_TqCmp_tqSumLossCmp: unqueued-receiver-com-spec{data-element=TqCmp_tqSumLossCmp, init-value=ConstantValue303, resync-time=0}, required-interface=IF_TqCmp_tqSumLossCmp  # Requirement: 01552_10_02369-CoTq.I101(0)
      R_TqCmp_tqSumLossCmpWoutCnv: unqueued-receiver-com-spec{data-element=TqCmp_tqSumLossCmpWoutCnv, init-value=ConstantValue305, resync-time=0}, required-interface=IF_TqCmp_tqSumLossCmpWoutCnv  # Requirement: 01552_10_02369-CoTq.I169(0)
      R_TqDem_facGainFil_nCk: unqueued-receiver-com-spec{data-element=TqDem_facGainFil_nCk, init-value=ConstantValue307, resync-time=0}, required-interface=IF_TqDem_facGainFil_nCk  # Requirement: 01552_10_02369-CoTq.I054(0)
      R_TqDem_tqCkEfc: unqueued-receiver-com-spec{data-element=TqDem_tqCkEfc, init-value=ConstantValue309, resync-time=0}, required-interface=IF_TqDem_tqCkEfc  # Requirement: 01552_10_02369-CoTq.I055(0)
      R_TqEst_tqIdcEstim: unqueued-receiver-com-spec{data-element=TqEst_tqIdcEstim, init-value=ConstantValue311, resync-time=0}, required-interface=IF_TqEst_tqIdcEstim  # Requirement: 01552_10_02369-CoTq.I170(0)
      R_TqLimEM_tqLimEM: unqueued-receiver-com-spec{data-element=TqLimEM_tqLimEM, init-value=ConstantValue313, resync-time=0}, required-interface=IF_TqLimEM_tqLimEM  # Requirement: 01552_10_02369-CoTq.I056(0)
      R_TqLimEM_tqLimEMExt: unqueued-receiver-com-spec{data-element=TqLimEM_tqLimEMExt, init-value=ConstantValue315, resync-time=0}, required-interface=IF_TqLimEM_tqLimEMExt  # Requirement: 01552_10_02369-CoTq.I057(0)
      R_TqLimEM_tqLimEMTrv: unqueued-receiver-com-spec{data-element=TqLimEM_tqLimEMTrv, init-value=ConstantValue317, resync-time=0}, required-interface=IF_TqLimEM_tqLimEMTrv  # Requirement: 01552_10_02369-CoTq.I102(0)
      R_TqSys_bAcceClrCrossAOSExt: unqueued-receiver-com-spec{data-element=TqSys_bAcceClrCrossAOSExt, init-value=ConstantValue319, resync-time=0}, required-interface=IF_TqSys_bAcceClrCrossAOSExt  # Requirement: 01552_10_02369-CoTq.I058(0)
      R_TqSys_bAcceClrCrossAOSIt: unqueued-receiver-com-spec{data-element=TqSys_bAcceClrCrossAOSIt, init-value=ConstantValue321, resync-time=0}, required-interface=IF_TqSys_bAcceClrCrossAOSIt  # Requirement: 01552_10_02369-CoTq.I059(0)
      R_TqSys_bAcceDetAOSExt: unqueued-receiver-com-spec{data-element=TqSys_bAcceDetAOSExt, init-value=ConstantValue323, resync-time=0}, required-interface=IF_TqSys_bAcceDetAOSExt  # Requirement: 01552_10_02369-CoTq.I060(0)
      R_TqSys_bAcceDetAOSIt: unqueued-receiver-com-spec{data-element=TqSys_bAcceDetAOSIt, init-value=ConstantValue325, resync-time=0}, required-interface=IF_TqSys_bAcceDetAOSIt  # Requirement: 01552_10_02369-CoTq.I061(0)
      R_TqSys_bAcvCllExt: unqueued-receiver-com-spec{data-element=TqSys_bAcvCllExt, init-value=ConstantValue327, resync-time=0}, required-interface=IF_TqSys_bAcvCllExt  # Requirement: 01552_10_02369-CoTq.I062(0)
      R_TqSys_bAcvCllIt: unqueued-receiver-com-spec{data-element=TqSys_bAcvCllIt, init-value=ConstantValue329, resync-time=0}, required-interface=IF_TqSys_bAcvCllIt  # Requirement: 01552_10_02369-CoTq.I063(0)
      R_TqSys_bDeceAcvExt: unqueued-receiver-com-spec{data-element=TqSys_bDeceAcvExt, init-value=ConstantValue331, resync-time=0}, required-interface=IF_TqSys_bDeceAcvExt  # Requirement: 01552_10_02369-CoTq.I064(0)
      R_TqSys_bDeceAcvIt: unqueued-receiver-com-spec{data-element=TqSys_bDeceAcvIt, init-value=ConstantValue333, resync-time=0}, required-interface=IF_TqSys_bDeceAcvIt  # Requirement: 01552_10_02369-CoTq.I065(0)
      R_TqSys_bDeceDetAOSExt: unqueued-receiver-com-spec{data-element=TqSys_bDeceDetAOSExt, init-value=ConstantValue335, resync-time=0}, required-interface=IF_TqSys_bDeceDetAOSExt  # Requirement: 01552_10_02369-CoTq.I066(0)
      R_TqSys_bDeceDetAOSIt: unqueued-receiver-com-spec{data-element=TqSys_bDeceDetAOSIt, init-value=ConstantValue337, resync-time=0}, required-interface=IF_TqSys_bDeceDetAOSIt  # Requirement: 01552_10_02369-CoTq.I067(0)
      R_TqSys_bFuCutOffReq: unqueued-receiver-com-spec{data-element=TqSys_bFuCutOffReq, init-value=ConstantValue339, resync-time=0}, required-interface=IF_TqSys_bFuCutOffReq  # Requirement: 01552_10_02369-CoTq.I103(0)
      R_TqSys_bTypFu: unqueued-receiver-com-spec{data-element=TqSys_bTypFu, init-value=ConstantValue341, resync-time=0}, required-interface=IF_TqSys_bTypFu  # Requirement: 01552_10_02369-CoTq.I007(0)
      R_TqSys_noCylCutAuthExt: unqueued-receiver-com-spec{data-element=TqSys_noCylCutAuthExt, init-value=ConstantValue343, resync-time=0}, required-interface=IF_TqSys_noCylCutAuthExt  # Requirement: 01552_10_02369-CoTq.I068(0)
      R_TqSys_noCylCutAuthIt: unqueued-receiver-com-spec{data-element=TqSys_noCylCutAuthIt, init-value=ConstantValue345, resync-time=0}, required-interface=IF_TqSys_noCylCutAuthIt  # Requirement: 01552_10_02369-CoTq.I069(0)
      R_TqSys_stDrivFilPhaExt: unqueued-receiver-com-spec{data-element=TqSys_stDrivFilPhaExt, init-value=ConstantValue347, resync-time=0}, required-interface=IF_TqSys_stDrivFilPhaExt  # Requirement: 01552_10_02369-CoTq.I071(0)
      R_TqSys_stDrivFilPhaIt: unqueued-receiver-com-spec{data-element=TqSys_stDrivFilPhaIt, init-value=ConstantValue349, resync-time=0}, required-interface=IF_TqSys_stDrivFilPhaIt  # Requirement: 01552_10_02369-CoTq.I072(0)
      R_TqSys_stTypPwtCf: unqueued-receiver-com-spec{data-element=TqSys_stTypPwtCf, init-value=ConstantValue351, resync-time=0}, required-interface=IF_TqSys_stTypPwtCf  # Requirement: 01552_10_02369-CoTq.I073(0)
      R_TqSys_tiTranCllExt: unqueued-receiver-com-spec{data-element=TqSys_tiTranCllExt, init-value=ConstantValue353, resync-time=0}, required-interface=IF_TqSys_tiTranCllExt  # Requirement: 01552_10_02369-CoTq.I074(0)
      R_TqSys_tiTranCllIt: unqueued-receiver-com-spec{data-element=TqSys_tiTranCllIt, init-value=ConstantValue355, resync-time=0}, required-interface=IF_TqSys_tiTranCllIt  # Requirement: 01552_10_02369-CoTq.I075(0)
      R_TqSys_tqCkDeceIniExt: unqueued-receiver-com-spec{data-element=TqSys_tqCkDeceIniExt, init-value=ConstantValue357, resync-time=0}, required-interface=IF_TqSys_tqCkDeceIniExt  # Requirement: 01552_10_02369-CoTq.I076(0)
      R_TqSys_tqCkDeceIniIt: unqueued-receiver-com-spec{data-element=TqSys_tqCkDeceIniIt, init-value=ConstantValue359, resync-time=0}, required-interface=IF_TqSys_tqCkDeceIniIt  # Requirement: 01552_10_02369-CoTq.I077(0)
      R_TqSys_tqCkEfcFil: unqueued-receiver-com-spec{data-element=TqSys_tqCkEfcFil, init-value=ConstantValue361, resync-time=0}, required-interface=IF_TqSys_tqCkEfcFil  # Requirement: 01552_10_02369-CoTq.I078(0)
      R_TqSys_tqCkEfcFilExt: unqueued-receiver-com-spec{data-element=TqSys_tqCkEfcFilExt, init-value=ConstantValue363, resync-time=0}, required-interface=IF_TqSys_tqCkEfcFilExt  # Requirement: 01552_10_02369-CoTq.I079(0)
      R_TqSys_tqCkEngLimCord: unqueued-receiver-com-spec{data-element=TqSys_tqCkEngLimCord, init-value=ConstantValue365, resync-time=0}, required-interface=IF_TqSys_tqCkEngLimCord  # Requirement: 01552_10_02369-CoTq.I173(0)
      R_TqSys_tqCkIdlCmn: unqueued-receiver-com-spec{data-element=TqSys_tqCkIdlCmn, init-value=ConstantValue367, resync-time=0}, required-interface=IF_TqSys_tqCkIdlCmn  # Requirement: 01552_10_02369-CoTq.I174(0)
      R_TqSys_tqIdcReq: unqueued-receiver-com-spec{data-element=TqSys_tqIdcReq, init-value=ConstantValue369, resync-time=0}, required-interface=IF_TqSys_tqIdcReq  # Requirement: 01552_10_02369-CoTq.I175(0)
      R_TqSys_tqIncCllExt: unqueued-receiver-com-spec{data-element=TqSys_tqIncCllExt, init-value=ConstantValue371, resync-time=0}, required-interface=IF_TqSys_tqIncCllExt  # Requirement: 01552_10_02369-CoTq.I080(0)
      R_TqSys_tqIncCllIt: unqueued-receiver-com-spec{data-element=TqSys_tqIncCllIt, init-value=ConstantValue373, resync-time=0}, required-interface=IF_TqSys_tqIncCllIt  # Requirement: 01552_10_02369-CoTq.I081(0)
      R_TqSys_tqThdPha3Ext: unqueued-receiver-com-spec{data-element=TqSys_tqThdPha3Ext, init-value=ConstantValue375, resync-time=0}, required-interface=IF_TqSys_tqThdPha3Ext  # Requirement: 01552_10_02369-CoTq.I082(0)
      R_TqSys_tqThdPha3It: unqueued-receiver-com-spec{data-element=TqSys_tqThdPha3It, init-value=ConstantValue377, resync-time=0}, required-interface=IF_TqSys_tqThdPha3It  # Requirement: 01552_10_02369-CoTq.I083(0)
      R_TreatTDC_nCkFil: unqueued-receiver-com-spec{data-element=TreatTDC_nCkFil, init-value=ConstantValue379, resync-time=0}, required-interface=IF_TreatTDC_nCkFil  # Requirement: 01552_10_02369-CoTq.I176(0)
      R_TreatTDC_nCkGrdFil: unqueued-receiver-com-spec{data-element=TreatTDC_nCkGrdFil, init-value=ConstantValue381, resync-time=0}, required-interface=IF_TreatTDC_nCkGrdFil  # Requirement: 01552_10_02369-CoTq.I177(0)
      R_UCE_stSt: required-interface=IF_UCE_stSt  # Requirement: 01552_09_00532-SSTG-C011(0)
      R_Veh_spdVeh: unqueued-receiver-com-spec{data-element=Veh_spdVeh, init-value=ConstantValue383, resync-time=0}, required-interface=IF_Veh_spdVeh  # Requirement: 01552_10_02369-CoTq.I178(0)
  194 x constant specification:
    C_Boolean_False
      value:
        boolean literal C_Boolean_False: type=DT_TqSys_bAcvTqCnv_irv, value=false
    ConstantValue
      value:
        boolean literal ConstantValue: type=DT_COTQ_bSynchCoherFlag, value=true
    ConstantValue1
      value:
        boolean literal ConstantValue1: type=DT_CoCha_bAcvCll, value=false
    ConstantValue101
      value:
        integer literal ConstantValue101: type=DT_TqDem_facGainFilTrv_nCk, value=1024
    ConstantValue103
      value:
        integer literal ConstantValue103: type=DT_TqDem_tqCkEfcTrv, value=0
    ConstantValue105
      value:
        integer literal ConstantValue105: type=DT_TqLimEM_tqIdcLimEM, value=0
    ConstantValue107
      value:
        integer literal ConstantValue107: type=DT_TqLimEM_tqLimEMTrv, value=0
    ConstantValue109
      value:
        boolean literal ConstantValue109: type=DT_TqSys_bAcceClrCrossAOS, value=false
    ConstantValue11
      value:
        boolean literal ConstantValue11: type=DT_CoPt_bAcvNRegReqBuf, value=false
    ConstantValue111
      value:
        boolean literal ConstantValue111: type=DT_TqSys_bAcceDetAOS, value=false
    ConstantValue113
      value:
        boolean literal ConstantValue113: type=DT_TqSys_bAcvCll, value=false
    ConstantValue115
      value:
        boolean literal ConstantValue115: type=DT_TqSys_bDeceAcv, value=false
    ConstantValue117
      value:
        boolean literal ConstantValue117: type=DT_TqSys_bDeceDetAOS, value=false
    ConstantValue119
      value:
        boolean literal ConstantValue119: type=DT_TqSys_bEngAsiReqTrv, value=false
    ConstantValue121
      value:
        boolean literal ConstantValue121: type=DT_TqSys_bInhEGR, value=false
    ConstantValue123
      value:
        boolean literal ConstantValue123: type=DT_TqSys_bRstAOS, value=false
    ConstantValue125
      value:
        integer literal ConstantValue125: type=DT_TqSys_noCylCutAuth, value=0
    ConstantValue127
      value:
        integer literal ConstantValue127: type=DT_TqSys_rLdEngRef, value=0
    ConstantValue129
      value:
        integer literal ConstantValue129: type=DT_TqSys_stDrivFilPha, value=0
    ConstantValue13
      value:
        boolean literal ConstantValue13: type=DT_CoPt_bDeacCll, value=false
    ConstantValue131
      value:
        integer literal ConstantValue131: type=DT_TqSys_tiTranCll, value=0
    ConstantValue133
      value:
        integer literal ConstantValue133: type=DT_TqSys_tqCkDeceIni, value=0
    ConstantValue135
      value:
        integer literal ConstantValue135: type=DT_TqSys_tqCkEfcFilTrv, value=0
    ConstantValue137
      value:
        integer literal ConstantValue137: type=DT_TqSys_tqCkEfcMinFeas, value=0
    ConstantValue139
      value:
        integer literal ConstantValue139: type=DT_TqSys_tqCkEfcReq, value=0
    ConstantValue141
      value:
        integer literal ConstantValue141: type=DT_TqSys_tqCkEngReal, value=0
    ConstantValue143
      value:
        integer literal ConstantValue143: type=DT_TqSys_tqCkEngRealEM, value=0
    ConstantValue145
      value:
        integer literal ConstantValue145: type=DT_TqSys_tqEfcAirIdl, value=0
    ConstantValue147
      value:
        integer literal ConstantValue147: type=DT_TqSys_tqEfcEngWoutAOS, value=0
    ConstantValue149
      value:
        integer literal ConstantValue149: type=DT_TqSys_tqEfcIdl, value=0
    ConstantValue15
      value:
        boolean literal ConstantValue15: type=DT_CoPt_bDeacCllBuf, value=false
    ConstantValue151
      value:
        integer literal ConstantValue151: type=DT_TqSys_tqIdcAirLim, value=32000
    ConstantValue153
      value:
        integer literal ConstantValue153: type=DT_TqSys_tqIncCll, value=0
    ConstantValue155
      value:
        integer literal ConstantValue155: type=DT_TqSys_tqThdPha3, value=0
    ConstantValue157
      value:
        boolean literal ConstantValue157: type=DT_CoCha_bAcvCllIt, value=false
    ConstantValue159
      value:
        boolean literal ConstantValue159: type=DT_CoCha_bInhEGR, value=false
    ConstantValue161
      value:
        boolean literal ConstantValue161: type=DT_CoCha_bInhEGRExt, value=false
    ConstantValue163
      value:
        boolean literal ConstantValue163: type=DT_CoCha_bInhEGRTrv, value=false
    ConstantValue165
      value:
        boolean literal ConstantValue165: type=DT_CoCha_bRstAOS, value=false
    ConstantValue167
      value:
        integer literal ConstantValue167: type=DT_CoCha_noCylCutAuthIt, value=0
    ConstantValue169
      value:
        integer literal ConstantValue169: type=DT_CoCha_tiTranCllIt, value=0
    ConstantValue17
      value:
        boolean literal ConstantValue17: type=DT_CoPt_bInjCutDynAuth1, value=false
    ConstantValue171
      value:
        integer literal ConstantValue171: type=DT_CoCha_tqIncCllIt, value=0
    ConstantValue173
      value:
        boolean literal ConstantValue173: type=DT_CoPTSt_bMainEngStopReq, value=false
    ConstantValue175
      value:
        integer literal ConstantValue175: type=DT_CoPTSt_stEng, value=1
    ConstantValue177
      value:
        boolean literal ConstantValue177: type=DT_CoPtUH_bEngAsiReq, value=false
    ConstantValue179
      value:
        boolean literal ConstantValue179: type=DT_CoPtUH_bEngAsiReqExt, value=false
    ConstantValue181
      value:
        boolean literal ConstantValue181: type=DT_CoPt_bAcvNRegReq, value=false
    ConstantValue183
      value:
        boolean literal ConstantValue183: type=DT_CoPt_bDeacCll, value=false
    ConstantValue185
      value:
        boolean literal ConstantValue185: type=DT_CoPt_bDeacCllExt, value=false
    ConstantValue187
      value:
        boolean literal ConstantValue187: type=DT_CoPt_bDeacCllIt, value=false
    ConstantValue189
      value:
        boolean literal ConstantValue189: type=DT_CoPt_bInhEGR, value=false
    ConstantValue19
      value:
        boolean literal ConstantValue19: type=DT_CoPt_bInjCutDynAuth2, value=false
    ConstantValue191
      value:
        boolean literal ConstantValue191: type=DT_CoPt_bSIP, value=false
    ConstantValue193
      value:
        integer literal ConstantValue193: type=DT_CoPt_nTar, value=3000
    ConstantValue195
      value:
        integer literal ConstantValue195: type=DT_CoPt_noTarGearCordIt, value=0
    ConstantValue197
      value:
        integer literal ConstantValue197: type=DT_CoPt_tqAirCord_tqGBx, value=0
    ConstantValue199
      value:
        integer literal ConstantValue199: type=DT_CoPt_tqAirMaxGBx, value=32000
    ConstantValue201
      value:
        integer literal ConstantValue201: type=DT_CoPt_tqCord_tqGBx, value=0
    ConstantValue203
      value:
        integer literal ConstantValue203: type=DT_CoPt_tqEfcAirCordLimExtTqGBx, value=0
    ConstantValue205
      value:
        integer literal ConstantValue205: type=DT_CoPt_tqEfcAirCordLimIt_tqGBx, value=0
    ConstantValue207
      value:
        integer literal ConstantValue207: type=DT_CoPt_tqEfcAirCordLim_tqGBx, value=0
    ConstantValue209
      value:
        integer literal ConstantValue209: type=DT_CoPt_tqEfcCordLimExt_tqGBx, value=0
    ConstantValue21
      value:
        boolean literal ConstantValue21: type=DT_CoPt_bSIPBuf, value=false
    ConstantValue211
      value:
        integer literal ConstantValue211: type=DT_CoPt_tqEfcCordLimIt_tqGBx, value=0
    ConstantValue213
      value:
        integer literal ConstantValue213: type=DT_CoPt_tqEfcCordLim_tqGBx, value=0
    ConstantValue215
      value:
        integer literal ConstantValue215: type=DT_CoPt_tqIdcCordLim_tqGBx, value=0
    ConstantValue217
      value:
        integer literal ConstantValue217: type=DT_CoPt_tqIdcMaxGBx, value=32000
    ConstantValue219
      value:
        integer literal ConstantValue219: type=DT_CoPt_tqIdcReqCord_nRegReq, value=0
    ConstantValue221
      value:
        integer literal ConstantValue221: type=DT_CoPt_tqMaxGBx, value=0
    ConstantValue223
      value:
        integer literal ConstantValue223: type=DT_CoPt_tqMaxGBx_nReg, value=0
    ConstantValue225
      value:
        integer literal ConstantValue225: type=DT_CoVSCtl_rAccPEng, value=0
    ConstantValue227
      value:
        integer literal ConstantValue227: type=DT_CoVSCtl_rAccPEngExt, value=0
    ConstantValue229
      value:
        integer literal ConstantValue229: type=DT_EOM_tiEngStop, value=864000
    ConstantValue23
      value:
        integer literal ConstantValue23: type=DT_CoPt_nTarBuf, value=3000
    ConstantValue231
      value:
        integer literal ConstantValue231: type=DT_EV_CoTq_011_DRE, value=0
    ConstantValue233
      value:
        integer literal ConstantValue233: type=DT_EngLim_tqCkEfcAirGBxLimCord, value=32000
    ConstantValue235
      value:
        integer literal ConstantValue235: type=DT_EngLim_tqCkEfcAirLim, value=32000
    ConstantValue237
      value:
        integer literal ConstantValue237: type=DT_EngLim_tqCkEfcGBxLimCord, value=32000
    ConstantValue239
      value:
        integer literal ConstantValue239: type=DT_EngLim_tqCkEfcStatLimExt, value=0
    ConstantValue241
      value:
        integer literal ConstantValue241: type=DT_EngLim_tqCkEfcStatLimIt, value=0
    ConstantValue243
      value:
        integer literal ConstantValue243: type=DT_EngLim_tqIdcEngCur, value=0
    ConstantValue245
      value:
        integer literal ConstantValue245: type=DT_EngLim_tqIdcEngCurGBx, value=0
    ConstantValue247
      value:
        integer literal ConstantValue247: type=DT_EngLim_tqIdcEngCurMax, value=32000
    ConstantValue249
      value:
        integer literal ConstantValue249: type=DT_EngLim_tqIdcEngCurMin, value=0
    ConstantValue25
      value:
        integer literal ConstantValue25: type=DT_CoPt_noTarGearCordBuf, value=0
    ConstantValue251
      value:
        integer literal ConstantValue251: type=DT_EngLim_tqIdcEngCurMinSelc, value=0
    ConstantValue253
      value:
        integer literal ConstantValue253: type=DT_EngLim_tqIdcEngLim, value=32000
    ConstantValue255
      value:
        integer literal ConstantValue255: type=DT_EngLim_tqIdcEngLimMax, value=32000
    ConstantValue257
      value:
        integer literal ConstantValue257: type=DT_EngLim_tqIdcEngProt, value=32000
    ConstantValue259
      value:
        integer literal ConstantValue259: type=DT_EngLim_tqIdcFLdLim, value=32000
    ConstantValue261
      value:
        integer literal ConstantValue261: type=DT_EngLim_tqIdcLdMaxTrbMax, value=32000
    ConstantValue263
      value:
        integer literal ConstantValue263: type=DT_EngLim_tqIdcLdMaxTrbMaxNoOvb, value=0
    ConstantValue265
      value:
        integer literal ConstantValue265: type=DT_EngLim_tqIdcLdMinAdvMin, value=0
    ConstantValue267
      value:
        integer literal ConstantValue267: type=DT_EngLim_tqIdcLdMinAdvMinSelc, value=0
    ConstantValue269
      value:
        integer literal ConstantValue269: type=DT_EngLim_tqIdcMaxNReg, value=32000
    ConstantValue27
      value:
        integer literal ConstantValue27: type=DT_CoPt_tqEfcAirCordLimIt_tqGBx, value=0
    ConstantValue271
      value:
        integer literal ConstantValue271: type=DT_EngLim_tqIdcPresUsThrMax, value=32000
    ConstantValue273
      value:
        integer literal ConstantValue273: type=DT_EngLim_tqIdcRed, value=0
    ConstantValue275
      value:
        integer literal ConstantValue275: type=DT_EngLim_tqIdcSfty, value=32000
    ConstantValue277
      value:
        integer literal ConstantValue277: type=DT_EngLim_tqIdcSmkLim, value=32000
    ConstantValue279
      value:
        integer literal ConstantValue279: type=DT_EngLim_tqIdcSyst, value=0
    ConstantValue281
      value:
        integer literal ConstantValue281: type=DT_Ext_nEng, value=0
    ConstantValue283
      value:
        integer literal ConstantValue283: type=DT_Ext_pAirExtMes, value=500
    ConstantValue285
      value:
        integer literal ConstantValue285: type=DT_Ext_stTraTypCf, value=0
    ConstantValue287
      value:
        integer literal ConstantValue287: type=DT_Ext_tAir, value=20
    ConstantValue289
      value:
        integer literal ConstantValue289: type=DT_Ext_tCoMes, value=20
    ConstantValue29
      value:
        integer literal ConstantValue29: type=DT_CoPt_tqEfcAirCordLim_tqGBx, value=0
    ConstantValue291
      value:
        integer literal ConstantValue291: type=DT_Ext_tOilMes, value=0
    ConstantValue293
      value:
        integer literal ConstantValue293: type=DT_Ext_tiTDC, value=100
    ConstantValue295
      value:
        integer literal ConstantValue295: type=DT_IdlSys_tqIdcAirIdl, value=0
    ConstantValue297
      value:
        integer literal ConstantValue297: type=DT_InjSys_tqIdcMinFeas, value=32000
    ConstantValue299
      value:
        integer literal ConstantValue299: type=DT_ThMgt_tqIdcLimReq, value=0
    ConstantValue3
      value:
        boolean literal ConstantValue3: type=DT_CoCha_bInhEGRTrv, value=false
    ConstantValue301
      value:
        integer literal ConstantValue301: type=DT_TqCmp_tqAltLoss, value=0
    ConstantValue303
      value:
        integer literal ConstantValue303: type=DT_TqCmp_tqSumLossCmp, value=0
    ConstantValue305
      value:
        integer literal ConstantValue305: type=DT_TqCmp_tqSumLossCmpWoutCnv, value=0
    ConstantValue307
      value:
        integer literal ConstantValue307: type=DT_TqDem_facGainFil_nCk, value=0
    ConstantValue309
      value:
        integer literal ConstantValue309: type=DT_TqDem_tqCkEfc, value=0
    ConstantValue31
      value:
        integer literal ConstantValue31: type=DT_CoPt_tqEfcCordLimIt_tqGBx, value=0
    ConstantValue311
      value:
        integer literal ConstantValue311: type=DT_TqEst_tqIdcEstim, value=0
    ConstantValue313
      value:
        integer literal ConstantValue313: type=DT_TqLimEM_tqLimEM, value=0
    ConstantValue315
      value:
        integer literal ConstantValue315: type=DT_TqLimEM_tqLimEMExt, value=0
    ConstantValue317
      value:
        integer literal ConstantValue317: type=DT_TqLimEM_tqLimEMTrv, value=0
    ConstantValue319
      value:
        boolean literal ConstantValue319: type=DT_TqSys_bAcceClrCrossAOSExt, value=false
    ConstantValue321
      value:
        boolean literal ConstantValue321: type=DT_TqSys_bAcceClrCrossAOSIt, value=false
    ConstantValue323
      value:
        boolean literal ConstantValue323: type=DT_TqSys_bAcceDetAOSExt, value=false
    ConstantValue325
      value:
        boolean literal ConstantValue325: type=DT_TqSys_bAcceDetAOSIt, value=false
    ConstantValue327
      value:
        boolean literal ConstantValue327: type=DT_TqSys_bAcvCllExt, value=false
    ConstantValue329
      value:
        boolean literal ConstantValue329: type=DT_TqSys_bAcvCllIt, value=false
    ConstantValue33
      value:
        integer literal ConstantValue33: type=DT_CoPt_tqEfcCordLim_tqGBx, value=0
    ConstantValue331
      value:
        boolean literal ConstantValue331: type=DT_TqSys_bDeceAcvExt, value=false
    ConstantValue333
      value:
        boolean literal ConstantValue333: type=DT_TqSys_bDeceAcvIt, value=false
    ConstantValue335
      value:
        boolean literal ConstantValue335: type=DT_TqSys_bDeceDetAOSExt, value=false
    ConstantValue337
      value:
        boolean literal ConstantValue337: type=DT_TqSys_bDeceDetAOSIt, value=false
    ConstantValue339
      value:
        boolean literal ConstantValue339: type=DT_TqSys_bFuCutOffReq, value=false
    ConstantValue341
      value:
        boolean literal ConstantValue341: type=DT_TqSys_bTypFu, value=false
    ConstantValue343
      value:
        integer literal ConstantValue343: type=DT_TqSys_noCylCutAuthExt, value=0
    ConstantValue345
      value:
        integer literal ConstantValue345: type=DT_TqSys_noCylCutAuthIt, value=0
    ConstantValue347
      value:
        integer literal ConstantValue347: type=DT_TqSys_stDrivFilPhaExt, value=0
    ConstantValue349
      value:
        integer literal ConstantValue349: type=DT_TqSys_stDrivFilPhaIt, value=0
    ConstantValue35
      value:
        integer literal ConstantValue35: type=DT_CoPt_tqEfcReqCord_nRegReq, value=0
    ConstantValue351
      value:
        integer literal ConstantValue351: type=DT_TqSys_stTypPwtCf, value=0
    ConstantValue353
      value:
        integer literal ConstantValue353: type=DT_TqSys_tiTranCllExt, value=0
    ConstantValue355
      value:
        integer literal ConstantValue355: type=DT_TqSys_tiTranCllIt, value=0
    ConstantValue357
      value:
        integer literal ConstantValue357: type=DT_TqSys_tqCkDeceIniExt, value=0
    ConstantValue359
      value:
        integer literal ConstantValue359: type=DT_TqSys_tqCkDeceIniIt, value=0
    ConstantValue361
      value:
        integer literal ConstantValue361: type=DT_TqSys_tqCkEfcFil, value=0
    ConstantValue363
      value:
        integer literal ConstantValue363: type=DT_TqSys_tqCkEfcFilExt, value=0
    ConstantValue365
      value:
        integer literal ConstantValue365: type=DT_TqSys_tqCkEngLimCord, value=0
    ConstantValue367
      value:
        integer literal ConstantValue367: type=DT_TqSys_tqCkIdlCmn, value=0
    ConstantValue369
      value:
        integer literal ConstantValue369: type=DT_TqSys_tqIdcReq, value=0
    ConstantValue37
      value:
        integer literal ConstantValue37: type=DT_CoPt_tqIdcAirCordLim_tqGBx, value=0
    ConstantValue371
      value:
        integer literal ConstantValue371: type=DT_TqSys_tqIncCllExt, value=0
    ConstantValue373
      value:
        integer literal ConstantValue373: type=DT_TqSys_tqIncCllIt, value=0
    ConstantValue375
      value:
        integer literal ConstantValue375: type=DT_TqSys_tqThdPha3Ext, value=0
    ConstantValue377
      value:
        integer literal ConstantValue377: type=DT_TqSys_tqThdPha3It, value=0
    ConstantValue379
      value:
        integer literal ConstantValue379: type=DT_TreatTDC_nCkFil, value=0
    ConstantValue381
      value:
        integer literal ConstantValue381: type=DT_TreatTDC_nCkGrdFil, value=0
    ConstantValue383
      value:
        integer literal ConstantValue383: type=DT_Veh_spdVeh, value=0
    ConstantValue39
      value:
        integer literal ConstantValue39: type=DT_CoPt_tqIdcAirMaxGBx, value=32000
    ConstantValue41
      value:
        integer literal ConstantValue41: type=DT_CoPt_tqIdcCordLimBuf_tqGBx, value=0
    ConstantValue43
      value:
        integer literal ConstantValue43: type=DT_CoPt_tqIdcCordLim_tqGBx, value=0
    ConstantValue45
      value:
        integer literal ConstantValue45: type=DT_CoPt_tqIdcMaxGBx, value=32000
    ConstantValue47
      value:
        integer literal ConstantValue47: type=DT_CoPt_tqIdcMaxGBxBuf, value=32000
    ConstantValue49
      value:
        integer literal ConstantValue49: type=DT_CoPt_tqMaxGBx_nRegBuf, value=32000
    ConstantValue5
      value:
        integer literal ConstantValue5: type=DT_CoCha_noCylCutAuth, value=0
    ConstantValue51
      value:
        integer literal ConstantValue51: type=DT_CoVSCtl_rAccPEngTrv, value=0
    ConstantValue53
      value:
        integer literal ConstantValue53: type=DT_EngLim_tqCkEfcFLdLim, value=32000
    ConstantValue55
      value:
        integer literal ConstantValue55: type=DT_EngLim_tqCkEfcLim, value=32000
    ConstantValue57
      value:
        integer literal ConstantValue57: type=DT_EngLim_tqCkEfcSmkLim, value=32000
    ConstantValue59
      value:
        integer literal ConstantValue59: type=DT_EngLim_tqCkEfcStatLim, value=32000
    ConstantValue61
      value:
        integer literal ConstantValue61: type=DT_EngLim_tqEfcCurMinFuCutSel, value=0
    ConstantValue63
      value:
        integer literal ConstantValue63: type=DT_EngLim_tqEfcEngCurMax, value=32000
    ConstantValue65
      value:
        integer literal ConstantValue65: type=DT_EngLim_tqEfcEngCurMin, value=0
    ConstantValue67
      value:
        integer literal ConstantValue67: type=DT_EngLim_tqEfcEngLim, value=32000
    ConstantValue69
      value:
        integer literal ConstantValue69: type=DT_EngLim_tqEfcEngLimCmb, value=32000
    ConstantValue7
      value:
        integer literal ConstantValue7: type=DT_CoCha_tiTranCll, value=0
    ConstantValue71
      value:
        integer literal ConstantValue71: type=DT_EngLim_tqEfcEngProt, value=32000
    ConstantValue73
      value:
        integer literal ConstantValue73: type=DT_EngLim_tqEfcLdAdvMinFuCutSel, value=0
    ConstantValue75
      value:
        integer literal ConstantValue75: type=DT_EngLim_tqEfcLdMaxTrbMax, value=32000
    ConstantValue77
      value:
        integer literal ConstantValue77: type=DT_EngLim_tqEfcLdMaxWoutOvb, value=32000
    ConstantValue79
      value:
        integer literal ConstantValue79: type=DT_EngLim_tqEfcLdMinAdvMin, value=0
    ConstantValue81
      value:
        integer literal ConstantValue81: type=DT_EngLim_tqEfcMaxEngLimCmb, value=32000
    ConstantValue83
      value:
        integer literal ConstantValue83: type=DT_EngLim_tqEfcMaxNReg, value=0
    ConstantValue85
      value:
        integer literal ConstantValue85: type=DT_EngLim_tqEfcMinCurCutOffTrv, value=0
    ConstantValue87
      value:
        integer literal ConstantValue87: type=DT_EngLim_tqEfcMinCurTrv, value=0
    ConstantValue89
      value:
        integer literal ConstantValue89: type=DT_EngLim_tqEfcMinEngLimCmb, value=0
    ConstantValue9
      value:
        integer literal ConstantValue9: type=DT_CoCha_tqIncCll, value=0
    ConstantValue91
      value:
        integer literal ConstantValue91: type=DT_EngLim_tqEfcPresUsThrMax, value=32000
    ConstantValue93
      value:
        integer literal ConstantValue93: type=DT_EngLim_tqEfcRed, value=32000
    ConstantValue95
      value:
        integer literal ConstantValue95: type=DT_EngLim_tqEfcSfty, value=32000
    ConstantValue97
      value:
        integer literal ConstantValue97: type=DT_EngLim_tqEfcSyst, value=32000
    ConstantValue99
      value:
        integer literal ConstantValue99: type=DT_ThMgt_tqEfcLimAntiBoilProt, value=32000
  internal behavior IB_CoTq: component=COTQ
    mode switch event EV_CoTq_001_MSE: start-on-event=RE_CoTq_001_MSE, activation=ENTRY, mode=R_EcuM_CurrentMode.currentMode.RUN
    data received event EV_CoTq_011_DRE: mode-dependency=dependent-on-mode=[R_UCE_stSt.RCD_Mode.COM_LATCH, R_UCE_stSt.RCD_Mode.INTERNAL_PARTIAL_WAKEUP, R_UCE_stSt.RCD_Mode.INTERNAL_PARTIAL_WAKEUP_APC, R_UCE_stSt.RCD_Mode.PARTIAL_WAKEUP, R_UCE_stSt.RCD_Mode.SHUTDOWN_PREPARATION, R_UCE_stSt.RCD_Mode.SHUTDOWN_PREPARATION_APC, R_UCE_stSt.RCD_Mode.TRANSITORY], start-on-event=RE_CoTq_011_DRE, data=R_EV_CoTq_011_DRE.EV_CoTq_011_DRE
    timing event EV_CoTq_002_TEV: mode-dependency=dependent-on-mode=[R_UCE_stSt.RCD_Mode.COM_LATCH, R_UCE_stSt.RCD_Mode.INTERNAL_PARTIAL_WAKEUP, R_UCE_stSt.RCD_Mode.INTERNAL_PARTIAL_WAKEUP_APC, R_UCE_stSt.RCD_Mode.PARTIAL_WAKEUP, R_UCE_stSt.RCD_Mode.SHUTDOWN_PREPARATION, R_UCE_stSt.RCD_Mode.SHUTDOWN_PREPARATION_APC, R_UCE_stSt.RCD_Mode.TRANSITORY], start-on-event=RE_CoTq_002_TEV, period=0.01
    timing event EV_CoTq_006_TEV: mode-dependency=dependent-on-mode=[R_UCE_stSt.RCD_Mode.COM_LATCH, R_UCE_stSt.RCD_Mode.INTERNAL_PARTIAL_WAKEUP, R_UCE_stSt.RCD_Mode.INTERNAL_PARTIAL_WAKEUP_APC, R_UCE_stSt.RCD_Mode.PARTIAL_WAKEUP, R_UCE_stSt.RCD_Mode.SHUTDOWN_PREPARATION, R_UCE_stSt.RCD_Mode.SHUTDOWN_PREPARATION_APC, R_UCE_stSt.RCD_Mode.TRANSITORY], start-on-event=RE_CoTq_006_TEV, period=0.01
    timing event EV_CoTq_004_TEV: mode-dependency=dependent-on-mode=[R_UCE_stSt.RCD_Mode.COM_LATCH, R_UCE_stSt.RCD_Mode.INTERNAL_PARTIAL_WAKEUP, R_UCE_stSt.RCD_Mode.INTERNAL_PARTIAL_WAKEUP_APC, R_UCE_stSt.RCD_Mode.PARTIAL_WAKEUP, R_UCE_stSt.RCD_Mode.SHUTDOWN_PREPARATION, R_UCE_stSt.RCD_Mode.SHUTDOWN_PREPARATION_APC, R_UCE_stSt.RCD_Mode.TRANSITORY], start-on-event=RE_CoTq_004_TEV, period=0.01
    4 x mode switch event, all with activation=ENTRY, mode=R_EcuM_CurrentMode.currentMode.RUN:
      EV_CoTq_009_MSE: start-on-event=RE_CoTq_009_MSE
      EV_CoTq_007_MSE: start-on-event=RE_CoTq_007_MSE
      EV_CoTq_005_MSE: start-on-event=RE_CoTq_005_MSE
      EV_CoTq_003_MSE: start-on-event=RE_CoTq_003_MSE
    timing event EV_CoTq_010_TEV: mode-dependency=dependent-on-mode=[R_UCE_stSt.RCD_Mode.COM_LATCH, R_UCE_stSt.RCD_Mode.INTERNAL_PARTIAL_WAKEUP, R_UCE_stSt.RCD_Mode.INTERNAL_PARTIAL_WAKEUP_APC, R_UCE_stSt.RCD_Mode.PARTIAL_WAKEUP, R_UCE_stSt.RCD_Mode.SHUTDOWN_PREPARATION, R_UCE_stSt.RCD_Mode.SHUTDOWN_PREPARATION_APC, R_UCE_stSt.RCD_Mode.TRANSITORY], start-on-event=RE_CoTq_010_TEV, period=0.01
    timing event EV_CoTq_008_TEV: mode-dependency=dependent-on-mode=[R_UCE_stSt.RCD_Mode.COM_LATCH, R_UCE_stSt.RCD_Mode.INTERNAL_PARTIAL_WAKEUP, R_UCE_stSt.RCD_Mode.INTERNAL_PARTIAL_WAKEUP_APC, R_UCE_stSt.RCD_Mode.PARTIAL_WAKEUP, R_UCE_stSt.RCD_Mode.SHUTDOWN_PREPARATION, R_UCE_stSt.RCD_Mode.SHUTDOWN_PREPARATION_APC, R_UCE_stSt.RCD_Mode.TRANSITORY], start-on-event=RE_CoTq_008_TEV, period=0.01
    inter runnable variable TqSys_bAcvTqCnv_irv: sw-calibration-access=READ-WRITE, type=DT_TqSys_bAcvTqCnv_irv, communication-approach=EXPLICIT, init-value=C_Boolean_False
    11 x runnable:
      RE_CoTq_010_TEV  # RE_062168_10ms
        13 x data receive point:
          dr_CoPt_tqEfcCordLim_tqGBx: data-element=R_CoPt_tqEfcCordLim_tqGBx.CoPt_tqEfcCordLim_tqGBx
          dr_TqSys_bTypFu: data-element=R_TqSys_bTypFu.TqSys_bTypFu
          dr_CoPt_bSIP: data-element=R_CoPt_bSIP.CoPt_bSIP
          dr_TqSys_tqCkEfcFil: data-element=R_TqSys_tqCkEfcFil.TqSys_tqCkEfcFil
          dr_TqLimEM_tqLimEM: data-element=R_TqLimEM_tqLimEM.TqLimEM_tqLimEM
          dr_CoPt_bDeacCll: data-element=R_CoPt_bDeacCll.CoPt_bDeacCll
          dr_TqCmp_tqSumLossCmp: data-element=R_TqCmp_tqSumLossCmp.TqCmp_tqSumLossCmp
          dr_CoPt_tqMaxGBx_nReg: data-element=R_CoPt_tqMaxGBx_nReg.CoPt_tqMaxGBx_nReg
          dr_CoPt_tqIdcCordLim_tqGBx: data-element=R_CoPt_tqIdcCordLim_tqGBx.CoPt_tqIdcCordLim_tqGBx
          dr_CoPt_bAcvNRegReq: data-element=R_CoPt_bAcvNRegReq.CoPt_bAcvNRegReq
          dr_CoPt_tqIdcMaxGBx: data-element=R_CoPt_tqIdcMaxGBx.CoPt_tqIdcMaxGBx
          dr_CoPt_noTarGearCordIt: data-element=R_CoPt_noTarGearCordIt.CoPt_noTarGearCordIt
          dr_CoPt_nTar: data-element=R_CoPt_nTar.CoPt_nTar
        11 x data send point:
          ds_CoPt_bSIPBuf: data-element=P_CoPt_bSIPBuf.CoPt_bSIPBuf
          ds_CoPt_tqIdcMaxGBxBuf: data-element=P_CoPt_tqIdcMaxGBxBuf.CoPt_tqIdcMaxGBxBuf
          ds_CoPt_bInjCutDynAuth2: data-element=P_CoPt_bInjCutDynAuth2.CoPt_bInjCutDynAuth2
          ds_CoPt_noTarGearCordBuf: data-element=P_CoPt_noTarGearCordBuf.CoPt_noTarGearCordBuf
          ds_CoPt_tqMaxGBx_nRegBuf: data-element=P_CoPt_tqMaxGBx_nRegBuf.CoPt_tqMaxGBx_nRegBuf
          ds_COTQ_bSynchCoherFlag: data-element=P_COTQ_bSynchCoherFlag.COTQ_bSynchCoherFlag
          ds_CoPt_bDeacCllBuf: data-element=P_CoPt_bDeacCllBuf.CoPt_bDeacCllBuf
          ds_CoPt_bAcvNRegReqBuf: data-element=P_CoPt_bAcvNRegReqBuf.CoPt_bAcvNRegReqBuf
          ds_CoPt_nTarBuf: data-element=P_CoPt_nTarBuf.CoPt_nTarBuf
          ds_CoPt_tqIdcCordLimBuf_tqGBx: data-element=P_CoPt_tqIdcCordLimBuf_tqGBx.CoPt_tqIdcCordLimBuf_tqGBx
          ds_CoPt_bInjCutDynAuth1: data-element=P_CoPt_bInjCutDynAuth1.CoPt_bInjCutDynAuth1
        sync call ssp_GetTimer_1ms_U32: operation=R_CoTq_GetTimer_1ms_U32.GetTimer_1ms_U32
      RE_CoTq_002_TEV  # RE_062167_10ms
        5 x data receive point:
          dr_CoPt_tqAirCord_tqGBx: data-element=R_CoPt_tqAirCord_tqGBx.CoPt_tqAirCord_tqGBx
          dr_EngLim_tqCkEfcGBxLimCord: data-element=R_EngLim_tqCkEfcGBxLimCord.EngLim_tqCkEfcGBxLimCord
          dr_CoPt_tqCord_tqGBx: data-element=R_CoPt_tqCord_tqGBx.CoPt_tqCord_tqGBx
          dr_TqSys_bTypFu: data-element=R_TqSys_bTypFu.TqSys_bTypFu
          dr_EngLim_tqCkEfcAirGBxLimCord: data-element=R_EngLim_tqCkEfcAirGBxLimCord.EngLim_tqCkEfcAirGBxLimCord
        data send point ds_CoPt_tqEfcAirCordLimIt_tqGBx: data-element=P_CoPt_tqEfcAirCordLimIt_tqGBx.CoPt_tqEfcAirCordLimIt_tqGBx
        data send point ds_CoPt_tqEfcCordLimIt_tqGBx: data-element=P_CoPt_tqEfcCordLimIt_tqGBx.CoPt_tqEfcCordLimIt_tqGBx
        sync call ssp_GetTimer_1ms_U32: operation=R_CoTq_GetTimer_1ms_U32.GetTimer_1ms_U32
      RE_CoTq_011_DRE: read-variable=TqSys_bAcvTqCnv_irv  # RE_080922_sync
        27 x data receive point:
          dr_TqCmp_tqSumLossCmp: data-element=R_TqCmp_tqSumLossCmp.TqCmp_tqSumLossCmp
          dr_TreatTDC_nCkFil: data-element=R_TreatTDC_nCkFil.TreatTDC_nCkFil
          dr_CoPTSt_bMainEngStopReq: data-element=R_CoPTSt_bMainEngStopReq.CoPTSt_bMainEngStopReq
          dr_TqCmp_tqSumLossCmpWoutCnv: data-element=R_TqCmp_tqSumLossCmpWoutCnv.TqCmp_tqSumLossCmpWoutCnv
          dr_TqLimEM_tqLimEMTrv: data-element=R_TqLimEM_tqLimEMTrv.TqLimEM_tqLimEMTrv
          dr_TqCmp_tqAltLoss: data-element=R_TqCmp_tqAltLoss.TqCmp_tqAltLoss
          dr_TqSys_tqCkEngLimCord: data-element=R_TqSys_tqCkEngLimCord.TqSys_tqCkEngLimCord
          dr_EngLim_tqIdcLdMinAdvMin: data-element=R_EngLim_tqIdcLdMinAdvMin.EngLim_tqIdcLdMinAdvMin
          dr_Veh_spdVeh: data-element=R_Veh_spdVeh.Veh_spdVeh
          dr_EngLim_tqIdcLdMinAdvMinSelc: data-element=R_EngLim_tqIdcLdMinAdvMinSelc.EngLim_tqIdcLdMinAdvMinSelc
          dr_EngLim_tqIdcFLdLim: data-element=R_EngLim_tqIdcFLdLim.EngLim_tqIdcFLdLim
          dr_Ext_tCoMes: data-element=R_Ext_tCoMes.Ext_tCoMes
          dr_TreatTDC_nCkGrdFil: data-element=R_TreatTDC_nCkGrdFil.TreatTDC_nCkGrdFil
          dr_EngLim_tqIdcMaxNReg: data-element=R_EngLim_tqIdcMaxNReg.EngLim_tqIdcMaxNReg
          dr_EngLim_tqIdcEngLimMax: data-element=R_EngLim_tqIdcEngLimMax.EngLim_tqIdcEngLimMax
          dr_EngLim_tqIdcLdMaxTrbMax: data-element=R_EngLim_tqIdcLdMaxTrbMax.EngLim_tqIdcLdMaxTrbMax
          dr_Ext_tOilMes: data-element=R_Ext_tOilMes.Ext_tOilMes
          dr_EOM_tiEngStop: data-element=R_EOM_tiEngStop.EOM_tiEngStop
          dr_CoPTSt_stEng: data-element=R_CoPTSt_stEng.CoPTSt_stEng
          dr_TqSys_bTypFu: data-element=R_TqSys_bTypFu.TqSys_bTypFu
          dr_TqEst_tqIdcEstim: data-element=R_TqEst_tqIdcEstim.TqEst_tqIdcEstim
          dr_CoPt_tqIdcReqCord_nRegReq: data-element=R_CoPt_tqIdcReqCord_nRegReq.CoPt_tqIdcReqCord_nRegReq
          dr_InjSys_tqIdcMinFeas: data-element=R_InjSys_tqIdcMinFeas.InjSys_tqIdcMinFeas
          dr_EngLim_tqIdcEngCur: data-element=R_EngLim_tqIdcEngCur.EngLim_tqIdcEngCur
          dr_EngLim_tqIdcEngCurGBx: data-element=R_EngLim_tqIdcEngCurGBx.EngLim_tqIdcEngCurGBx
          dr_Ext_tiTDC: data-element=R_Ext_tiTDC.Ext_tiTDC
          dr_EngLim_tqIdcPresUsThrMax: data-element=R_EngLim_tqIdcPresUsThrMax.EngLim_tqIdcPresUsThrMax
        11 x data send point:
          ds_EngLim_tqEfcLdAdvMinFuCutSel: data-element=P_EngLim_tqEfcLdAdvMinFuCutSel.EngLim_tqEfcLdAdvMinFuCutSel
          ds_TqSys_tqEfcEngWoutAOS: data-element=P_TqSys_tqEfcEngWoutAOS.TqSys_tqEfcEngWoutAOS
          ds_TqSys_tqCkEngRealEM: data-element=P_TqSys_tqCkEngRealEM.TqSys_tqCkEngRealEM
          ds_TqSys_tqCkEngReal: data-element=P_TqSys_tqCkEngReal.TqSys_tqCkEngReal
          ds_EngLim_tqEfcMaxEngLimCmb: data-element=P_EngLim_tqEfcMaxEngLimCmb.EngLim_tqEfcMaxEngLimCmb
          ds_EngLim_tqEfcEngLimCmb: data-element=P_EngLim_tqEfcEngLimCmb.EngLim_tqEfcEngLimCmb
          ds_EngLim_tqEfcEngLim: data-element=P_EngLim_tqEfcEngLim.EngLim_tqEfcEngLim
          ds_TqSys_tqCkEfcMinFeas: data-element=P_TqSys_tqCkEfcMinFeas.TqSys_tqCkEfcMinFeas
          ds_EngLim_tqEfcMaxNReg: data-element=P_EngLim_tqEfcMaxNReg.EngLim_tqEfcMaxNReg
          ds_EngLim_tqEfcLdMinAdvMin: data-element=P_EngLim_tqEfcLdMinAdvMin.EngLim_tqEfcLdMinAdvMin
          ds_CoPt_tqEfcReqCord_nRegReq: data-element=P_CoPt_tqEfcReqCord_nRegReq.CoPt_tqEfcReqCord_nRegReq
        sync call ssp_GetTimer_1ms_U32: operation=R_CoTq_GetTimer_1ms_U32.GetTimer_1ms_U32
      RE_CoTq_006_TEV  # RE_080921_10ms
        13 x data receive point:
          dr_EngLim_tqCkEfcAirLim: data-element=R_EngLim_tqCkEfcAirLim.EngLim_tqCkEfcAirLim
          dr_CoPt_bInhEGR: data-element=R_CoPt_bInhEGR.CoPt_bInhEGR
          dr_CoPt_tqMaxGBx: data-element=R_CoPt_tqMaxGBx.CoPt_tqMaxGBx
          dr_TqCmp_tqAltLoss: data-element=R_TqCmp_tqAltLoss.TqCmp_tqAltLoss
          dr_CoCha_bRstAOS: data-element=R_CoCha_bRstAOS.CoCha_bRstAOS
          dr_TqCmp_tqSumLossCmp: data-element=R_TqCmp_tqSumLossCmp.TqCmp_tqSumLossCmp
          dr_CoPt_tqAirMaxGBx: data-element=R_CoPt_tqAirMaxGBx.CoPt_tqAirMaxGBx
          dr_TqSys_bTypFu: data-element=R_TqSys_bTypFu.TqSys_bTypFu
          dr_TqLimEM_tqLimEMTrv: data-element=R_TqLimEM_tqLimEMTrv.TqLimEM_tqLimEMTrv
          dr_CoPt_tqEfcCordLim_tqGBx: data-element=R_CoPt_tqEfcCordLim_tqGBx.CoPt_tqEfcCordLim_tqGBx
          dr_TqSys_bFuCutOffReq: data-element=R_TqSys_bFuCutOffReq.TqSys_bFuCutOffReq
          dr_CoPt_tqEfcAirCordLim_tqGBx: data-element=R_CoPt_tqEfcAirCordLim_tqGBx.CoPt_tqEfcAirCordLim_tqGBx
          dr_CoCha_bInhEGRTrv: data-element=R_CoCha_bInhEGRTrv.CoCha_bInhEGRTrv
        8 x data send point:
          ds_TqSys_tqIdcAirLim: data-element=P_TqSys_tqIdcAirLim.TqSys_tqIdcAirLim
          ds_CoPt_tqIdcCordLim_tqGBx: data-element=P_CoPt_tqIdcCordLim_tqGBx.CoPt_tqIdcCordLim_tqGBx
          ds_TqLimEM_tqIdcLimEM: data-element=P_TqLimEM_tqIdcLimEM.TqLimEM_tqIdcLimEM
          ds_CoPt_tqIdcAirMaxGBx: data-element=P_CoPt_tqIdcAirMaxGBx.CoPt_tqIdcAirMaxGBx
          ds_TqSys_bInhEGR: data-element=P_TqSys_bInhEGR.TqSys_bInhEGR
          ds_TqSys_bRstAOS: data-element=P_TqSys_bRstAOS.TqSys_bRstAOS
          ds_CoPt_tqIdcMaxGBx: data-element=P_CoPt_tqIdcMaxGBx.CoPt_tqIdcMaxGBx
          ds_CoPt_tqIdcAirCordLim_tqGBx: data-element=P_CoPt_tqIdcAirCordLim_tqGBx.CoPt_tqIdcAirCordLim_tqGBx
        sync call ssp_GetTimer_1ms_U32: operation=R_CoTq_GetTimer_1ms_U32.GetTimer_1ms_U32
      RE_CoTq_005_MSE  # RE_080921_10ms_init
        8 x data send point:
          ds_CoPt_tqIdcAirMaxGBx: data-element=P_CoPt_tqIdcAirMaxGBx.CoPt_tqIdcAirMaxGBx
          ds_TqSys_bRstAOS: data-element=P_TqSys_bRstAOS.TqSys_bRstAOS
          ds_CoPt_tqIdcMaxGBx: data-element=P_CoPt_tqIdcMaxGBx.CoPt_tqIdcMaxGBx
          ds_TqSys_tqIdcAirLim: data-element=P_TqSys_tqIdcAirLim.TqSys_tqIdcAirLim
          ds_TqSys_bInhEGR: data-element=P_TqSys_bInhEGR.TqSys_bInhEGR
          ds_CoPt_tqIdcCordLim_tqGBx: data-element=P_CoPt_tqIdcCordLim_tqGBx.CoPt_tqIdcCordLim_tqGBx
          ds_TqLimEM_tqIdcLimEM: data-element=P_TqLimEM_tqIdcLimEM.TqLimEM_tqIdcLimEM
          ds_CoPt_tqIdcAirCordLim_tqGBx: data-element=P_CoPt_tqIdcAirCordLim_tqGBx.CoPt_tqIdcAirCordLim_tqGBx
        sync call ssp_GetTimer_1ms_U32: operation=R_CoTq_GetTimer_1ms_U32.GetTimer_1ms_U32
      RE_CoTq_008_TEV: written-variable=TqSys_bAcvTqCnv_irv  # RE_080922_10ms
        44 x data receive point:
          dr_Ext_tOilMes: data-element=R_Ext_tOilMes.Ext_tOilMes
          dr_EngLim_tqIdcLdMaxTrbMaxNoOvb: data-element=R_EngLim_tqIdcLdMaxTrbMaxNoOvb.EngLim_tqIdcLdMaxTrbMaxNoOvb
          dr_CoPt_tqIdcReqCord_nRegReq: data-element=R_CoPt_tqIdcReqCord_nRegReq.CoPt_tqIdcReqCord_nRegReq
          dr_EngLim_tqIdcEngCurMax: data-element=R_EngLim_tqIdcEngCurMax.EngLim_tqIdcEngCurMax
          dr_EngLim_tqIdcEngCur: data-element=R_EngLim_tqIdcEngCur.EngLim_tqIdcEngCur
          dr_IdlSys_tqIdcAirIdl: data-element=R_IdlSys_tqIdcAirIdl.IdlSys_tqIdcAirIdl
          dr_EngLim_tqIdcLdMinAdvMin: data-element=R_EngLim_tqIdcLdMinAdvMin.EngLim_tqIdcLdMinAdvMin
          dr_TqLimEM_tqLimEMTrv: data-element=R_TqLimEM_tqLimEMTrv.TqLimEM_tqLimEMTrv
          dr_EngLim_tqIdcRed: data-element=R_EngLim_tqIdcRed.EngLim_tqIdcRed
          dr_EngLim_tqIdcLdMinAdvMinSelc: data-element=R_EngLim_tqIdcLdMinAdvMinSelc.EngLim_tqIdcLdMinAdvMinSelc
          dr_TqEst_tqIdcEstim: data-element=R_TqEst_tqIdcEstim.TqEst_tqIdcEstim
          dr_InjSys_tqIdcMinFeas: data-element=R_InjSys_tqIdcMinFeas.InjSys_tqIdcMinFeas
          dr_TqCmp_tqSumLossCmpWoutCnv: data-element=R_TqCmp_tqSumLossCmpWoutCnv.TqCmp_tqSumLossCmpWoutCnv
          dr_Ext_tiTDC: data-element=R_Ext_tiTDC.Ext_tiTDC
          dr_Ext_nEng: data-element=R_Ext_nEng.Ext_nEng
          dr_EngLim_tqIdcSfty: data-element=R_EngLim_tqIdcSfty.EngLim_tqIdcSfty
          dr_CoPTSt_stEng: data-element=R_CoPTSt_stEng.CoPTSt_stEng
          dr_TqCmp_tqAltLoss: data-element=R_TqCmp_tqAltLoss.TqCmp_tqAltLoss
          dr_Ext_tAir: data-element=R_Ext_tAir.Ext_tAir
          dr_TreatTDC_nCkGrdFil: data-element=R_TreatTDC_nCkGrdFil.TreatTDC_nCkGrdFil
          dr_TqSys_tqCkEngLimCord: data-element=R_TqSys_tqCkEngLimCord.TqSys_tqCkEngLimCord
          dr_EngLim_tqIdcPresUsThrMax: data-element=R_EngLim_tqIdcPresUsThrMax.EngLim_tqIdcPresUsThrMax
          dr_EngLim_tqIdcSmkLim: data-element=R_EngLim_tqIdcSmkLim.EngLim_tqIdcSmkLim
          dr_EngLim_tqIdcEngCurGBx: data-element=R_EngLim_tqIdcEngCurGBx.EngLim_tqIdcEngCurGBx
          dr_TqSys_bTypFu: data-element=R_TqSys_bTypFu.TqSys_bTypFu
          dr_TqSys_tqCkIdlCmn: data-element=R_TqSys_tqCkIdlCmn.TqSys_tqCkIdlCmn
          dr_EngLim_tqIdcSyst: data-element=R_EngLim_tqIdcSyst.EngLim_tqIdcSyst
          dr_Ext_pAirExtMes: data-element=R_Ext_pAirExtMes.Ext_pAirExtMes
          dr_TqSys_tqIdcReq: data-element=R_TqSys_tqIdcReq.TqSys_tqIdcReq
          dr_TqCmp_tqSumLossCmp: data-element=R_TqCmp_tqSumLossCmp.TqCmp_tqSumLossCmp
          dr_EOM_tiEngStop: data-element=R_EOM_tiEngStop.EOM_tiEngStop
          dr_EngLim_tqIdcEngProt: data-element=R_EngLim_tqIdcEngProt.EngLim_tqIdcEngProt
          dr_EngLim_tqIdcEngCurMin: data-element=R_EngLim_tqIdcEngCurMin.EngLim_tqIdcEngCurMin
          dr_Ext_tCoMes: data-element=R_Ext_tCoMes.Ext_tCoMes
          dr_CoPTSt_bMainEngStopReq: data-element=R_CoPTSt_bMainEngStopReq.CoPTSt_bMainEngStopReq
          dr_EngLim_tqIdcEngCurMinSelc: data-element=R_EngLim_tqIdcEngCurMinSelc.EngLim_tqIdcEngCurMinSelc
          dr_EngLim_tqIdcMaxNReg: data-element=R_EngLim_tqIdcMaxNReg.EngLim_tqIdcMaxNReg
          dr_EngLim_tqIdcEngLim: data-element=R_EngLim_tqIdcEngLim.EngLim_tqIdcEngLim
          dr_Veh_spdVeh: data-element=R_Veh_spdVeh.Veh_spdVeh
          dr_ThMgt_tqIdcLimReq: data-element=R_ThMgt_tqIdcLimReq.ThMgt_tqIdcLimReq
          dr_TreatTDC_nCkFil: data-element=R_TreatTDC_nCkFil.TreatTDC_nCkFil
          dr_EngLim_tqIdcFLdLim: data-element=R_EngLim_tqIdcFLdLim.EngLim_tqIdcFLdLim
          dr_EngLim_tqIdcEngLimMax: data-element=R_EngLim_tqIdcEngLimMax.EngLim_tqIdcEngLimMax
          dr_EngLim_tqIdcLdMaxTrbMax: data-element=R_EngLim_tqIdcLdMaxTrbMax.EngLim_tqIdcLdMaxTrbMax
        32 x data send point:
          ds_TqSys_tqEfcAirIdl: data-element=P_TqSys_tqEfcAirIdl.TqSys_tqEfcAirIdl
          ds_TqSys_tqCkEngReal: data-element=P_TqSys_tqCkEngReal.TqSys_tqCkEngReal
          ds_EngLim_tqEfcMinCurTrv: data-element=P_EngLim_tqEfcMinCurTrv.EngLim_tqEfcMinCurTrv
          ds_EngLim_tqEfcEngCurMin: data-element=P_EngLim_tqEfcEngCurMin.EngLim_tqEfcEngCurMin
          ds_EngLim_tqEfcEngCurMax: data-element=P_EngLim_tqEfcEngCurMax.EngLim_tqEfcEngCurMax
          ds_EngLim_tqEfcSyst: data-element=P_EngLim_tqEfcSyst.EngLim_tqEfcSyst
          ds_EngLim_tqCkEfcSmkLim: data-element=P_EngLim_tqCkEfcSmkLim.EngLim_tqCkEfcSmkLim
          ds_EngLim_tqEfcMinCurCutOffTrv: data-element=P_EngLim_tqEfcMinCurCutOffTrv.EngLim_tqEfcMinCurCutOffTrv
          ds_TqSys_tqEfcIdl: data-element=P_TqSys_tqEfcIdl.TqSys_tqEfcIdl
          ds_EngLim_tqEfcLdMinAdvMin: data-element=P_EngLim_tqEfcLdMinAdvMin.EngLim_tqEfcLdMinAdvMin
          ds_EngLim_tqEfcLdMaxTrbMax: data-element=P_EngLim_tqEfcLdMaxTrbMax.EngLim_tqEfcLdMaxTrbMax
          ds_EngLim_tqEfcLdMaxWoutOvb: data-element=P_EngLim_tqEfcLdMaxWoutOvb.EngLim_tqEfcLdMaxWoutOvb
          ds_EngLim_tqEfcEngLim: data-element=P_EngLim_tqEfcEngLim.EngLim_tqEfcEngLim
          ds_TqSys_tqCkEfcReq: data-element=P_TqSys_tqCkEfcReq.TqSys_tqCkEfcReq
          ds_TqSys_tqEfcEngWoutAOS: data-element=P_TqSys_tqEfcEngWoutAOS.TqSys_tqEfcEngWoutAOS
          ds_TqSys_rLdEngRef: data-element=P_TqSys_rLdEngRef.TqSys_rLdEngRef
          ds_EngLim_tqEfcEngLimCmb: data-element=P_EngLim_tqEfcEngLimCmb.EngLim_tqEfcEngLimCmb
          ds_ThMgt_tqEfcLimAntiBoilProt: data-element=P_ThMgt_tqEfcLimAntiBoilProt.ThMgt_tqEfcLimAntiBoilProt
          ds_TqSys_tqCkEngRealEM: data-element=P_TqSys_tqCkEngRealEM.TqSys_tqCkEngRealEM
          ds_EngLim_tqEfcCurMinFuCutSel: data-element=P_EngLim_tqEfcCurMinFuCutSel.EngLim_tqEfcCurMinFuCutSel
          ds_EngLim_tqEfcLdAdvMinFuCutSel: data-element=P_EngLim_tqEfcLdAdvMinFuCutSel.EngLim_tqEfcLdAdvMinFuCutSel
          ds_EngLim_tqEfcSfty: data-element=P_EngLim_tqEfcSfty.EngLim_tqEfcSfty
          ds_EngLim_tqEfcMaxNReg: data-element=P_EngLim_tqEfcMaxNReg.EngLim_tqEfcMaxNReg
          ds_EngLim_tqEfcEngProt: data-element=P_EngLim_tqEfcEngProt.EngLim_tqEfcEngProt
          ds_EngLim_tqEfcPresUsThrMax: data-element=P_EngLim_tqEfcPresUsThrMax.EngLim_tqEfcPresUsThrMax
          ds_EngLim_tqCkEfcLim: data-element=P_EngLim_tqCkEfcLim.EngLim_tqCkEfcLim
          ds_EngLim_tqCkEfcFLdLim: data-element=P_EngLim_tqCkEfcFLdLim.EngLim_tqCkEfcFLdLim
          ds_CoPt_tqEfcReqCord_nRegReq: data-element=P_CoPt_tqEfcReqCord_nRegReq.CoPt_tqEfcReqCord_nRegReq
          ds_EngLim_tqEfcMinEngLimCmb: data-element=P_EngLim_tqEfcMinEngLimCmb.EngLim_tqEfcMinEngLimCmb
          ds_TqSys_tqCkEfcMinFeas: data-element=P_TqSys_tqCkEfcMinFeas.TqSys_tqCkEfcMinFeas
          ds_EngLim_tqEfcMaxEngLimCmb: data-element=P_EngLim_tqEfcMaxEngLimCmb.EngLim_tqEfcMaxEngLimCmb
          ds_EngLim_tqEfcRed: data-element=P_EngLim_tqEfcRed.EngLim_tqEfcRed
        sync call ssp_GetTimer_1ms_U32: operation=R_CoTq_GetTimer_1ms_U32.GetTimer_1ms_U32
      RE_CoTq_009_MSE  # RE_062168_10ms_init
        11 x data send point:
          ds_CoPt_bAcvNRegReqBuf: data-element=P_CoPt_bAcvNRegReqBuf.CoPt_bAcvNRegReqBuf
          ds_CoPt_tqIdcCordLimBuf_tqGBx: data-element=P_CoPt_tqIdcCordLimBuf_tqGBx.CoPt_tqIdcCordLimBuf_tqGBx
          ds_CoPt_nTarBuf: data-element=P_CoPt_nTarBuf.CoPt_nTarBuf
          ds_CoPt_bSIPBuf: data-element=P_CoPt_bSIPBuf.CoPt_bSIPBuf
          ds_CoPt_noTarGearCordBuf: data-element=P_CoPt_noTarGearCordBuf.CoPt_noTarGearCordBuf
          ds_CoPt_tqIdcMaxGBxBuf: data-element=P_CoPt_tqIdcMaxGBxBuf.CoPt_tqIdcMaxGBxBuf
          ds_CoPt_bInjCutDynAuth1: data-element=P_CoPt_bInjCutDynAuth1.CoPt_bInjCutDynAuth1
          ds_CoPt_bDeacCllBuf: data-element=P_CoPt_bDeacCllBuf.CoPt_bDeacCllBuf
          ds_CoPt_bInjCutDynAuth2: data-element=P_CoPt_bInjCutDynAuth2.CoPt_bInjCutDynAuth2
          ds_CoPt_tqMaxGBx_nRegBuf: data-element=P_CoPt_tqMaxGBx_nRegBuf.CoPt_tqMaxGBx_nRegBuf
          ds_COTQ_bSynchCoherFlag: data-element=P_COTQ_bSynchCoherFlag.COTQ_bSynchCoherFlag
        sync call ssp_GetTimer_1ms_U32: operation=R_CoTq_GetTimer_1ms_U32.GetTimer_1ms_U32
      RE_CoTq_004_TEV  # RE_081446_10ms
        48 x data receive point:
          dr_CoPtUH_bEngAsiReqExt: data-element=R_CoPtUH_bEngAsiReqExt.CoPtUH_bEngAsiReqExt
          dr_EngLim_tqCkEfcStatLimExt: data-element=R_EngLim_tqCkEfcStatLimExt.EngLim_tqCkEfcStatLimExt
          dr_TqSys_tiTranCllIt: data-element=R_TqSys_tiTranCllIt.TqSys_tiTranCllIt
          dr_TqDem_tqCkEfc: data-element=R_TqDem_tqCkEfc.TqDem_tqCkEfc
          dr_TqSys_noCylCutAuthIt: data-element=R_TqSys_noCylCutAuthIt.TqSys_noCylCutAuthIt
          dr_TqSys_bAcceDetAOSExt: data-element=R_TqSys_bAcceDetAOSExt.TqSys_bAcceDetAOSExt
          dr_Ext_stTraTypCf: data-element=R_Ext_stTraTypCf.Ext_stTraTypCf
          dr_CoPt_tqEfcCordLimExt_tqGBx: data-element=R_CoPt_tqEfcCordLimExt_tqGBx.CoPt_tqEfcCordLimExt_tqGBx
          dr_CoPtUH_bEngAsiReq: data-element=R_CoPtUH_bEngAsiReq.CoPtUH_bEngAsiReq
          dr_CoCha_bInhEGR: data-element=R_CoCha_bInhEGR.CoCha_bInhEGR
          dr_TqSys_stDrivFilPhaIt: data-element=R_TqSys_stDrivFilPhaIt.TqSys_stDrivFilPhaIt
          dr_TqSys_bDeceDetAOSIt: data-element=R_TqSys_bDeceDetAOSIt.TqSys_bDeceDetAOSIt
          dr_EngLim_tqCkEfcStatLimIt: data-element=R_EngLim_tqCkEfcStatLimIt.EngLim_tqCkEfcStatLimIt
          dr_CoCha_tqIncCllIt: data-element=R_CoCha_tqIncCllIt.CoCha_tqIncCllIt
          dr_TqSys_tqThdPha3It: data-element=R_TqSys_tqThdPha3It.TqSys_tqThdPha3It
          dr_TqLimEM_tqLimEM: data-element=R_TqLimEM_tqLimEM.TqLimEM_tqLimEM
          dr_CoPt_tqEfcAirCordLimIt_tqGBx: data-element=R_CoPt_tqEfcAirCordLimIt_tqGBx.CoPt_tqEfcAirCordLimIt_tqGBx
          dr_TqSys_tqCkDeceIniExt: data-element=R_TqSys_tqCkDeceIniExt.TqSys_tqCkDeceIniExt
          dr_TqSys_tqIncCllIt: data-element=R_TqSys_tqIncCllIt.TqSys_tqIncCllIt
          dr_CoPt_tqEfcCordLimIt_tqGBx: data-element=R_CoPt_tqEfcCordLimIt_tqGBx.CoPt_tqEfcCordLimIt_tqGBx
          dr_TqSys_tqCkEfcFilExt: data-element=R_TqSys_tqCkEfcFilExt.TqSys_tqCkEfcFilExt
          dr_TqSys_bDeceAcvExt: data-element=R_TqSys_bDeceAcvExt.TqSys_bDeceAcvExt
          dr_TqSys_tiTranCllExt: data-element=R_TqSys_tiTranCllExt.TqSys_tiTranCllExt
          dr_TqSys_tqIncCllExt: data-element=R_TqSys_tqIncCllExt.TqSys_tqIncCllExt
          dr_TqSys_noCylCutAuthExt: data-element=R_TqSys_noCylCutAuthExt.TqSys_noCylCutAuthExt
          dr_TqSys_bAcceClrCrossAOSExt: data-element=R_TqSys_bAcceClrCrossAOSExt.TqSys_bAcceClrCrossAOSExt
          dr_TqLimEM_tqLimEMExt: data-element=R_TqLimEM_tqLimEMExt.TqLimEM_tqLimEMExt
          dr_TqSys_bAcvCllExt: data-element=R_TqSys_bAcvCllExt.TqSys_bAcvCllExt
          dr_TqSys_tqCkEfcFil: data-element=R_TqSys_tqCkEfcFil.TqSys_tqCkEfcFil
          dr_CoCha_bInhEGRExt: data-element=R_CoCha_bInhEGRExt.CoCha_bInhEGRExt
          dr_CoCha_noCylCutAuthIt: data-element=R_CoCha_noCylCutAuthIt.CoCha_noCylCutAuthIt
          dr_TqDem_facGainFil_nCk: data-element=R_TqDem_facGainFil_nCk.TqDem_facGainFil_nCk
          dr_TqSys_stDrivFilPhaExt: data-element=R_TqSys_stDrivFilPhaExt.TqSys_stDrivFilPhaExt
          dr_TqSys_bDeceDetAOSExt: data-element=R_TqSys_bDeceDetAOSExt.TqSys_bDeceDetAOSExt
          dr_CoCha_bAcvCllIt: data-element=R_CoCha_bAcvCllIt.CoCha_bAcvCllIt
          dr_CoVSCtl_rAccPEng: data-element=R_CoVSCtl_rAccPEng.CoVSCtl_rAccPEng
          dr_TqSys_tqCkDeceIniIt: data-element=R_TqSys_tqCkDeceIniIt.TqSys_tqCkDeceIniIt
          dr_CoPt_tqEfcAirCordLimExtTqGBx: data-element=R_CoPt_tqEfcAirCordLimExtTqGBx.CoPt_tqEfcAirCordLimExtTqGBx
          dr_CoPt_bDeacCllIt: data-element=R_CoPt_bDeacCllIt.CoPt_bDeacCllIt
          dr_CoPt_bDeacCllExt: data-element=R_CoPt_bDeacCllExt.CoPt_bDeacCllExt
          dr_TqSys_stTypPwtCf: data-element=R_TqSys_stTypPwtCf.TqSys_stTypPwtCf
          dr_CoCha_tiTranCllIt: data-element=R_CoCha_tiTranCllIt.CoCha_tiTranCllIt
          dr_CoVSCtl_rAccPEngExt: data-element=R_CoVSCtl_rAccPEngExt.CoVSCtl_rAccPEngExt
          dr_TqSys_bAcvCllIt: data-element=R_TqSys_bAcvCllIt.TqSys_bAcvCllIt
          dr_TqSys_bDeceAcvIt: data-element=R_TqSys_bDeceAcvIt.TqSys_bDeceAcvIt
          dr_TqSys_tqThdPha3Ext: data-element=R_TqSys_tqThdPha3Ext.TqSys_tqThdPha3Ext
          dr_TqSys_bAcceClrCrossAOSIt: data-element=R_TqSys_bAcceClrCrossAOSIt.TqSys_bAcceClrCrossAOSIt
          dr_TqSys_bAcceDetAOSIt: data-element=R_TqSys_bAcceDetAOSIt.TqSys_bAcceDetAOSIt
        26 x data send point:
          ds_TqSys_bDeceAcv: data-element=P_TqSys_bDeceAcv.TqSys_bDeceAcv
          ds_TqSys_tqCkDeceIni: data-element=P_TqSys_tqCkDeceIni.TqSys_tqCkDeceIni
          ds_CoCha_tiTranCll: data-element=P_CoCha_tiTranCll.CoCha_tiTranCll
          ds_TqSys_tiTranCll: data-element=P_TqSys_tiTranCll.TqSys_tiTranCll
          ds_TqLimEM_tqLimEMTrv: data-element=P_TqLimEM_tqLimEMTrv.TqLimEM_tqLimEMTrv
          ds_TqSys_bAcceDetAOS: data-element=P_TqSys_bAcceDetAOS.TqSys_bAcceDetAOS
          ds_CoCha_bAcvCll: data-element=P_CoCha_bAcvCll.CoCha_bAcvCll
          ds_CoCha_tqIncCll: data-element=P_CoCha_tqIncCll.CoCha_tqIncCll
          ds_TqSys_tqThdPha3: data-element=P_TqSys_tqThdPha3.TqSys_tqThdPha3
          ds_TqSys_bEngAsiReqTrv: data-element=P_TqSys_bEngAsiReqTrv.TqSys_bEngAsiReqTrv
          ds_CoPt_tqEfcAirCordLim_tqGBx: data-element=P_CoPt_tqEfcAirCordLim_tqGBx.CoPt_tqEfcAirCordLim_tqGBx
          ds_CoCha_bInhEGRTrv: data-element=P_CoCha_bInhEGRTrv.CoCha_bInhEGRTrv
          ds_TqSys_stDrivFilPha: data-element=P_TqSys_stDrivFilPha.TqSys_stDrivFilPha
          ds_TqSys_bAcceClrCrossAOS: data-element=P_TqSys_bAcceClrCrossAOS.TqSys_bAcceClrCrossAOS
          ds_TqSys_tqCkEfcFilTrv: data-element=P_TqSys_tqCkEfcFilTrv.TqSys_tqCkEfcFilTrv
          ds_EngLim_tqCkEfcStatLim: data-element=P_EngLim_tqCkEfcStatLim.EngLim_tqCkEfcStatLim
          ds_TqDem_tqCkEfcTrv: data-element=P_TqDem_tqCkEfcTrv.TqDem_tqCkEfcTrv
          ds_TqSys_noCylCutAuth: data-element=P_TqSys_noCylCutAuth.TqSys_noCylCutAuth
          ds_TqDem_facGainFilTrv_nCk: data-element=P_TqDem_facGainFilTrv_nCk.TqDem_facGainFilTrv_nCk
          ds_CoPt_tqEfcCordLim_tqGBx: data-element=P_CoPt_tqEfcCordLim_tqGBx.CoPt_tqEfcCordLim_tqGBx
          ds_TqSys_bDeceDetAOS: data-element=P_TqSys_bDeceDetAOS.TqSys_bDeceDetAOS
          ds_CoCha_noCylCutAuth: data-element=P_CoCha_noCylCutAuth.CoCha_noCylCutAuth
          ds_CoPt_bDeacCll: data-element=P_CoPt_bDeacCll.CoPt_bDeacCll
          ds_TqSys_bAcvCll: data-element=P_TqSys_bAcvCll.TqSys_bAcvCll
          ds_TqSys_tqIncCll: data-element=P_TqSys_tqIncCll.TqSys_tqIncCll
          ds_CoVSCtl_rAccPEngTrv: data-element=P_CoVSCtl_rAccPEngTrv.CoVSCtl_rAccPEngTrv
        sync call ssp_GetTimer_1ms_U32: operation=R_CoTq_GetTimer_1ms_U32.GetTimer_1ms_U32
      RE_CoTq_003_MSE  # RE_081446_10ms_init
        26 x data send point:
          ds_TqSys_bDeceDetAOS: data-element=P_TqSys_bDeceDetAOS.TqSys_bDeceDetAOS
          ds_EngLim_tqCkEfcStatLim: data-element=P_EngLim_tqCkEfcStatLim.EngLim_tqCkEfcStatLim
          ds_CoPt_tqEfcAirCordLim_tqGBx: data-element=P_CoPt_tqEfcAirCordLim_tqGBx.CoPt_tqEfcAirCordLim_tqGBx
          ds_CoPt_bDeacCll: data-element=P_CoPt_bDeacCll.CoPt_bDeacCll
          ds_TqSys_bEngAsiReqTrv: data-element=P_TqSys_bEngAsiReqTrv.TqSys_bEngAsiReqTrv
          ds_TqLimEM_tqLimEMTrv: data-element=P_TqLimEM_tqLimEMTrv.TqLimEM_tqLimEMTrv
          ds_CoCha_bAcvCll: data-element=P_CoCha_bAcvCll.CoCha_bAcvCll
          ds_TqSys_bDeceAcv: data-element=P_TqSys_bDeceAcv.TqSys_bDeceAcv
          ds_CoPt_tqEfcCordLim_tqGBx: data-element=P_CoPt_tqEfcCordLim_tqGBx.CoPt_tqEfcCordLim_tqGBx
          ds_TqSys_noCylCutAuth: data-element=P_TqSys_noCylCutAuth.TqSys_noCylCutAuth
          ds_TqSys_tqCkDeceIni: data-element=P_TqSys_tqCkDeceIni.TqSys_tqCkDeceIni
          ds_TqSys_bAcceDetAOS: data-element=P_TqSys_bAcceDetAOS.TqSys_bAcceDetAOS
          ds_TqSys_tiTranCll: data-element=P_TqSys_tiTranCll.TqSys_tiTranCll
          ds_CoVSCtl_rAccPEngTrv: data-element=P_CoVSCtl_rAccPEngTrv.CoVSCtl_rAccPEngTrv
          ds_TqSys_stDrivFilPha: data-element=P_TqSys_stDrivFilPha.TqSys_stDrivFilPha
          ds_CoCha_tiTranCll: data-element=P_CoCha_tiTranCll.CoCha_tiTranCll
          ds_CoCha_bInhEGRTrv: data-element=P_CoCha_bInhEGRTrv.CoCha_bInhEGRTrv
          ds_TqSys_tqIncCll: data-element=P_TqSys_tqIncCll.TqSys_tqIncCll
          ds_TqSys_bAcceClrCrossAOS: data-element=P_TqSys_bAcceClrCrossAOS.TqSys_bAcceClrCrossAOS
          ds_CoCha_noCylCutAuth: data-element=P_CoCha_noCylCutAuth.CoCha_noCylCutAuth
          ds_TqSys_bAcvCll: data-element=P_TqSys_bAcvCll.TqSys_bAcvCll
          ds_CoCha_tqIncCll: data-element=P_CoCha_tqIncCll.CoCha_tqIncCll
          ds_TqSys_tqThdPha3: data-element=P_TqSys_tqThdPha3.TqSys_tqThdPha3
          ds_TqSys_tqCkEfcFilTrv: data-element=P_TqSys_tqCkEfcFilTrv.TqSys_tqCkEfcFilTrv
          ds_TqDem_facGainFilTrv_nCk: data-element=P_TqDem_facGainFilTrv_nCk.TqDem_facGainFilTrv_nCk
          ds_TqDem_tqCkEfcTrv: data-element=P_TqDem_tqCkEfcTrv.TqDem_tqCkEfcTrv
        sync call ssp_GetTimer_1ms_U32: operation=R_CoTq_GetTimer_1ms_U32.GetTimer_1ms_U32
      RE_CoTq_001_MSE  # RE_062167_10ms_init
        data send point ds_CoPt_tqEfcCordLimIt_tqGBx: data-element=P_CoPt_tqEfcCordLimIt_tqGBx.CoPt_tqEfcCordLimIt_tqGBx
        data send point ds_CoPt_tqEfcAirCordLimIt_tqGBx: data-element=P_CoPt_tqEfcAirCordLimIt_tqGBx.CoPt_tqEfcAirCordLimIt_tqGBx
        sync call ssp_GetTimer_1ms_U32: operation=R_CoTq_GetTimer_1ms_U32.GetTimer_1ms_U32
      RE_CoTq_007_MSE: written-variable=TqSys_bAcvTqCnv_irv  # RE_080922_10ms_init
        32 x data send point:
          ds_CoPt_tqEfcReqCord_nRegReq: data-element=P_CoPt_tqEfcReqCord_nRegReq.CoPt_tqEfcReqCord_nRegReq
          ds_EngLim_tqEfcMinEngLimCmb: data-element=P_EngLim_tqEfcMinEngLimCmb.EngLim_tqEfcMinEngLimCmb
          ds_TqSys_tqEfcEngWoutAOS: data-element=P_TqSys_tqEfcEngWoutAOS.TqSys_tqEfcEngWoutAOS
          ds_ThMgt_tqEfcLimAntiBoilProt: data-element=P_ThMgt_tqEfcLimAntiBoilProt.ThMgt_tqEfcLimAntiBoilProt
          ds_EngLim_tqEfcEngCurMax: data-element=P_EngLim_tqEfcEngCurMax.EngLim_tqEfcEngCurMax
          ds_TqSys_tqCkEngReal: data-element=P_TqSys_tqCkEngReal.TqSys_tqCkEngReal
          ds_EngLim_tqEfcEngLimCmb: data-element=P_EngLim_tqEfcEngLimCmb.EngLim_tqEfcEngLimCmb
          ds_EngLim_tqEfcMinCurTrv: data-element=P_EngLim_tqEfcMinCurTrv.EngLim_tqEfcMinCurTrv
          ds_TqSys_tqEfcAirIdl: data-element=P_TqSys_tqEfcAirIdl.TqSys_tqEfcAirIdl
          ds_EngLim_tqCkEfcSmkLim: data-element=P_EngLim_tqCkEfcSmkLim.EngLim_tqCkEfcSmkLim
          ds_EngLim_tqEfcEngProt: data-element=P_EngLim_tqEfcEngProt.EngLim_tqEfcEngProt
          ds_TqSys_tqEfcIdl: data-element=P_TqSys_tqEfcIdl.TqSys_tqEfcIdl
          ds_EngLim_tqCkEfcLim: data-element=P_EngLim_tqCkEfcLim.EngLim_tqCkEfcLim
          ds_TqSys_rLdEngRef: data-element=P_TqSys_rLdEngRef.TqSys_rLdEngRef
          ds_EngLim_tqEfcLdMaxWoutOvb: data-element=P_EngLim_tqEfcLdMaxWoutOvb.EngLim_tqEfcLdMaxWoutOvb
          ds_EngLim_tqCkEfcFLdLim: data-element=P_EngLim_tqCkEfcFLdLim.EngLim_tqCkEfcFLdLim
          ds_EngLim_tqEfcLdMaxTrbMax: data-element=P_EngLim_tqEfcLdMaxTrbMax.EngLim_tqEfcLdMaxTrbMax
          ds_TqSys_tqCkEfcMinFeas: data-element=P_TqSys_tqCkEfcMinFeas.TqSys_tqCkEfcMinFeas
          ds_EngLim_tqEfcMinCurCutOffTrv: data-element=P_EngLim_tqEfcMinCurCutOffTrv.EngLim_tqEfcMinCurCutOffTrv
          ds_TqSys_tqCkEfcReq: data-element=P_TqSys_tqCkEfcReq.TqSys_tqCkEfcReq
          ds_EngLim_tqEfcLdAdvMinFuCutSel: data-element=P_EngLim_tqEfcLdAdvMinFuCutSel.EngLim_tqEfcLdAdvMinFuCutSel
          ds_EngLim_tqEfcEngLim: data-element=P_EngLim_tqEfcEngLim.EngLim_tqEfcEngLim
          ds_EngLim_tqEfcSyst: data-element=P_EngLim_tqEfcSyst.EngLim_tqEfcSyst
          ds_EngLim_tqEfcMaxNReg: data-element=P_EngLim_tqEfcMaxNReg.EngLim_tqEfcMaxNReg
          ds_EngLim_tqEfcRed: data-element=P_EngLim_tqEfcRed.EngLim_tqEfcRed
          ds_EngLim_tqEfcLdMinAdvMin: data-element=P_EngLim_tqEfcLdMinAdvMin.EngLim_tqEfcLdMinAdvMin
          ds_EngLim_tqEfcSfty: data-element=P_EngLim_tqEfcSfty.EngLim_tqEfcSfty
          ds_EngLim_tqEfcMaxEngLimCmb: data-element=P_EngLim_tqEfcMaxEngLimCmb.EngLim_tqEfcMaxEngLimCmb
          ds_EngLim_tqEfcPresUsThrMax: data-element=P_EngLim_tqEfcPresUsThrMax.EngLim_tqEfcPresUsThrMax
          ds_EngLim_tqEfcEngCurMin: data-element=P_EngLim_tqEfcEngCurMin.EngLim_tqEfcEngCurMin
          ds_TqSys_tqCkEngRealEM: data-element=P_TqSys_tqCkEngRealEM.TqSys_tqCkEngRealEM
          ds_EngLim_tqEfcCurMinFuCutSel: data-element=P_EngLim_tqEfcCurMinFuCutSel.EngLim_tqEfcCurMinFuCutSel
        sync call ssp_GetTimer_1ms_U32: operation=R_CoTq_GetTimer_1ms_U32.GetTimer_1ms_U32
  swc implementation Imp_CoTq: programming-language=C, behavior=IB_CoTq
    code-descriptors:
      code CodeDescriptor: type=SRC
        10 x xfile:
          COTQ_Torque_Selection_c: url=COTQ_Torque_Selection.c
          CoTq_c: url=CoTq.c
          COTQ_Func_Call_c: url=COTQ_Func_Call.c
          COTQ_Cord_Lim_Torq_Struct_c: url=COTQ_Cord_Lim_Torq_Struct.c
          COTQ_Sync_Engine_Speed_c: url=COTQ_Sync_Engine_Speed.c
          COTQ_Tempo_Data_Synch_c: url=COTQ_Tempo_Data_Synch.c
          COTQ_Cme_Cmi_Convers_c: url=COTQ_Cme_Cmi_Convers.c
          COTQ_Conversion_10ms_c: url=COTQ_Conversion_10ms.c
          CoTq_MemMap_h: url=CoTq_MemMap.h
          CoTq_h: url=CoTq.h
package /Components/SWC_CoTq/CoTq_IRVDatatypes
  boolean type DT_TqSys_bAcvTqCnv_irv: base-type=boolean
